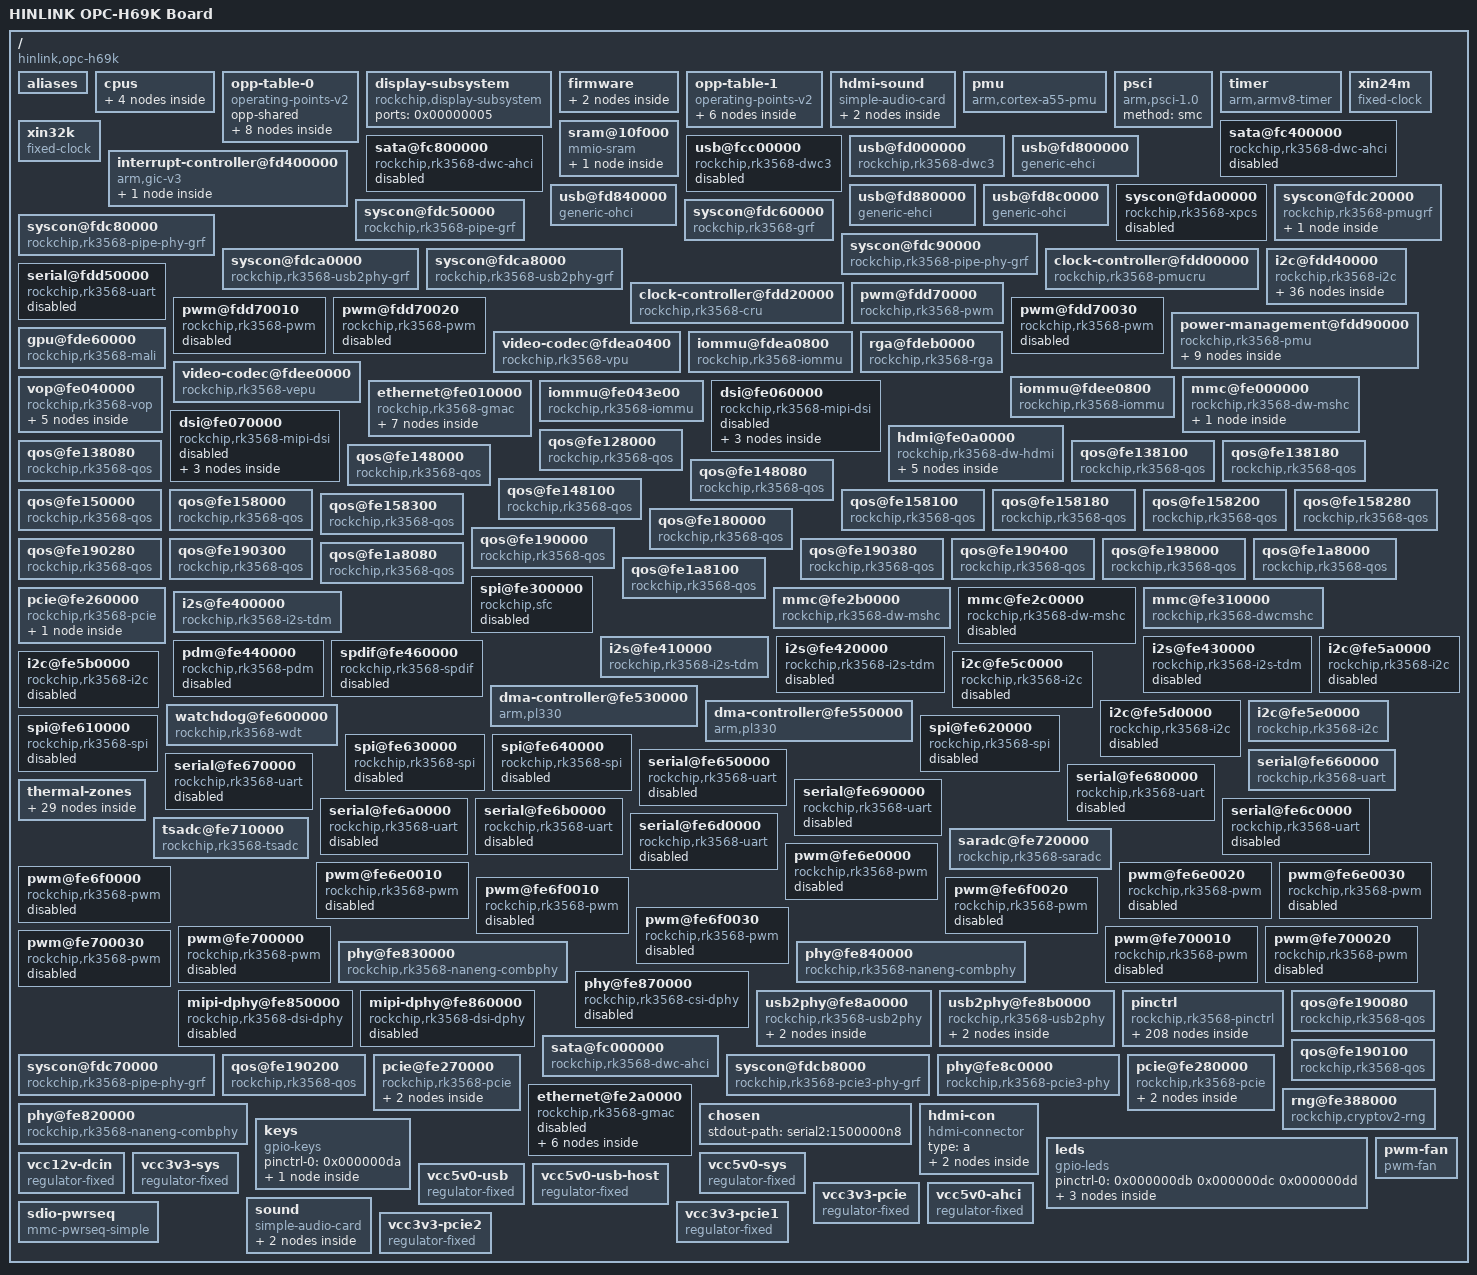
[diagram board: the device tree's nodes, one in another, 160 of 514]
/dts-v1/;
// version:		17
// last_comp_version:	16
// boot_cpuid_phys:	0x0

/ {
    interrupt-parent = <0x00000001>;
    #address-cells = <0x00000002>;
    #size-cells = <0x00000002>;
    compatible = "hinlink,opc-h69k", "rockchip,rk3568";
    model = "HINLINK OPC-H69K Board";
    aliases {
        gpio0 = "/pinctrl/gpio@fdd60000";
        gpio1 = "/pinctrl/gpio@fe740000";
        gpio2 = "/pinctrl/gpio@fe750000";
        gpio3 = "/pinctrl/gpio@fe760000";
        gpio4 = "/pinctrl/gpio@fe770000";
        i2c0 = "/i2c@fdd40000";
        i2c1 = "/i2c@fe5a0000";
        i2c2 = "/i2c@fe5b0000";
        i2c3 = "/i2c@fe5c0000";
        i2c4 = "/i2c@fe5d0000";
        i2c5 = "/i2c@fe5e0000";
        serial0 = "/serial@fdd50000";
        serial1 = "/serial@fe650000";
        serial2 = "/serial@fe660000";
        serial3 = "/serial@fe670000";
        serial4 = "/serial@fe680000";
        serial5 = "/serial@fe690000";
        serial6 = "/serial@fe6a0000";
        serial7 = "/serial@fe6b0000";
        serial8 = "/serial@fe6c0000";
        serial9 = "/serial@fe6d0000";
        spi0 = "/spi@fe610000";
        spi1 = "/spi@fe620000";
        spi2 = "/spi@fe630000";
        spi3 = "/spi@fe640000";
        mmc0 = "/mmc@fe310000";
        mmc1 = "/mmc@fe2b0000";
        led-boot = "/leds/work";
        led-failsafe = "/leds/work";
        led-running = "/leds/work";
        led-upgrade = "/leds/work";
        ethernet0 = "/ethernet@fe010000";
    };
    cpus {
        #address-cells = <0x00000002>;
        #size-cells = <0x00000000>;
        cpu@0 {
            device_type = "cpu";
            compatible = "arm,cortex-a55";
            reg = <0x00000000 0x00000000>;
            clocks = <0x00000002 0x00000000>;
            #cooling-cells = <0x00000002>;
            enable-method = "psci";
            operating-points-v2 = <0x00000003>;
            cpu-supply = <0x00000004>;
            phandle = <0x00000009>;
        };
        cpu@100 {
            device_type = "cpu";
            compatible = "arm,cortex-a55";
            reg = <0x00000000 0x00000100>;
            #cooling-cells = <0x00000002>;
            enable-method = "psci";
            operating-points-v2 = <0x00000003>;
            cpu-supply = <0x00000004>;
            phandle = <0x0000000a>;
        };
        cpu@200 {
            device_type = "cpu";
            compatible = "arm,cortex-a55";
            reg = <0x00000000 0x00000200>;
            #cooling-cells = <0x00000002>;
            enable-method = "psci";
            operating-points-v2 = <0x00000003>;
            cpu-supply = <0x00000004>;
            phandle = <0x0000000b>;
        };
        cpu@300 {
            device_type = "cpu";
            compatible = "arm,cortex-a55";
            reg = <0x00000000 0x00000300>;
            #cooling-cells = <0x00000002>;
            enable-method = "psci";
            operating-points-v2 = <0x00000003>;
            cpu-supply = <0x00000004>;
            phandle = <0x0000000c>;
        };
    };
    opp-table-0 {
        compatible = "operating-points-v2";
        opp-shared;
        phandle = <0x00000003>;
        opp-408000000 {
            opp-hz = <0x00000000 0x18519600>;
            opp-microvolt = <0x000dbba0 0x000dbba0 0x00118c30>;
            clock-latency-ns = <0x00009c40>;
        };
        opp-600000000 {
            opp-hz = <0x00000000 0x23c34600>;
            opp-microvolt = <0x000dbba0 0x000dbba0 0x00118c30>;
        };
        opp-816000000 {
            opp-hz = <0x00000000 0x30a32c00>;
            opp-microvolt = <0x000dbba0 0x000dbba0 0x00118c30>;
            opp-suspend;
        };
        opp-1104000000 {
            opp-hz = <0x00000000 0x41cdb400>;
            opp-microvolt = <0x000dbba0 0x000dbba0 0x00118c30>;
        };
        opp-1416000000 {
            opp-hz = <0x00000000 0x54667200>;
            opp-microvolt = <0x000dbba0 0x000dbba0 0x00118c30>;
        };
        opp-1608000000 {
            opp-hz = <0x00000000 0x5fd82200>;
            opp-microvolt = <0x000ee098 0x000ee098 0x00118c30>;
        };
        opp-1800000000 {
            opp-hz = <0x00000000 0x6b49d200>;
            opp-microvolt = <0x00100590 0x00100590 0x00118c30>;
        };
        opp-1992000000 {
            opp-hz = <0x00000000 0x76bb8200>;
            opp-microvolt = <0x00118c30 0x00118c30 0x00118c30>;
        };
    };
    display-subsystem {
        compatible = "rockchip,display-subsystem";
        ports = <0x00000005>;
    };
    firmware {
        scmi {
            compatible = "arm,scmi-smc";
            arm,smc-id = <0x82000010>;
            shmem = <0x00000006>;
            #address-cells = <0x00000001>;
            #size-cells = <0x00000000>;
            protocol@14 {
                reg = <0x00000014>;
                #clock-cells = <0x00000001>;
                phandle = <0x00000002>;
            };
        };
    };
    opp-table-1 {
        compatible = "operating-points-v2";
        phandle = <0x00000045>;
        opp-200000000 {
            opp-hz = <0x00000000 0x0bebc200>;
            opp-microvolt = <0x000cf850 0x000cf850 0x000f4240>;
        };
        opp-300000000 {
            opp-hz = <0x00000000 0x11e1a300>;
            opp-microvolt = <0x000cf850 0x000cf850 0x000f4240>;
        };
        opp-400000000 {
            opp-hz = <0x00000000 0x17d78400>;
            opp-microvolt = <0x000cf850 0x000cf850 0x000f4240>;
        };
        opp-600000000 {
            opp-hz = <0x00000000 0x23c34600>;
            opp-microvolt = <0x000dbba0 0x000dbba0 0x000f4240>;
        };
        opp-700000000 {
            opp-hz = <0x00000000 0x29b92700>;
            opp-microvolt = <0x000e7ef0 0x000e7ef0 0x000f4240>;
        };
        opp-800000000 {
            opp-hz = <0x00000000 0x2faf0800>;
            opp-microvolt = <0x000f4240 0x000f4240 0x000f4240>;
        };
    };
    hdmi-sound {
        compatible = "simple-audio-card";
        simple-audio-card,name = "HDMI";
        simple-audio-card,format = "i2s";
        simple-audio-card,mclk-fs = <0x00000100>;
        status = "okay";
        simple-audio-card,codec {
            sound-dai = <0x00000007>;
        };
        simple-audio-card,cpu {
            sound-dai = <0x00000008>;
        };
    };
    pmu {
        compatible = "arm,cortex-a55-pmu";
        interrupts = <0x00000000 0x000000e4 0x00000004 0x00000000 0x000000e5 0x00000004 0x00000000 0x000000e6 0x00000004 0x00000000 0x000000e7 0x00000004>;
        interrupt-affinity = <0x00000009 0x0000000a 0x0000000b 0x0000000c>;
    };
    psci {
        compatible = "arm,psci-1.0";
        method = "smc";
    };
    timer {
        compatible = "arm,armv8-timer";
        interrupts = <0x00000001 0x0000000d 0x00000004 0x00000001 0x0000000e 0x00000004 0x00000001 0x0000000b 0x00000004 0x00000001 0x0000000a 0x00000004>;
        arm,no-tick-in-suspend;
    };
    xin24m {
        compatible = "fixed-clock";
        clock-frequency = <0x016e3600>;
        clock-output-names = "xin24m";
        #clock-cells = <0x00000000>;
        phandle = <0x0000001c>;
    };
    xin32k {
        compatible = "fixed-clock";
        clock-frequency = <0x00008000>;
        clock-output-names = "xin32k";
        pinctrl-0 = <0x0000000d>;
        pinctrl-names = "default";
        #clock-cells = <0x00000000>;
    };
    sram@10f000 {
        compatible = "mmio-sram";
        reg = <0x00000000 0x0010f000 0x00000000 0x00000100>;
        #address-cells = <0x00000001>;
        #size-cells = <0x00000001>;
        ranges = <0x00000000 0x00000000 0x0010f000 0x00000100>;
        sram@0 {
            compatible = "arm,scmi-shmem";
            reg = <0x00000000 0x00000100>;
            phandle = <0x00000006>;
        };
    };
    sata@fc400000 {
        compatible = "rockchip,rk3568-dwc-ahci", "snps,dwc-ahci";
        reg = <0x00000000 0xfc400000 0x00000000 0x00001000>;
        clocks = <0x0000000e 0x0000009b 0x0000000e 0x0000009c 0x0000000e 0x0000009d>;
        clock-names = "sata", "pmalive", "rxoob";
        interrupts = <0x00000000 0x0000005f 0x00000004>;
        phys = <0x0000000f 0x00000001>;
        phy-names = "sata-phy";
        ports-implemented = <0x00000001>;
        power-domains = <0x00000010 0x0000000f>;
        status = "disabled";
    };
    sata@fc800000 {
        compatible = "rockchip,rk3568-dwc-ahci", "snps,dwc-ahci";
        reg = <0x00000000 0xfc800000 0x00000000 0x00001000>;
        clocks = <0x0000000e 0x000000a0 0x0000000e 0x000000a1 0x0000000e 0x000000a2>;
        clock-names = "sata", "pmalive", "rxoob";
        interrupts = <0x00000000 0x00000060 0x00000004>;
        phys = <0x00000011 0x00000001>;
        phy-names = "sata-phy";
        ports-implemented = <0x00000001>;
        power-domains = <0x00000010 0x0000000f>;
        status = "disabled";
    };
    usb@fcc00000 {
        compatible = "rockchip,rk3568-dwc3", "snps,dwc3";
        reg = <0x00000000 0xfcc00000 0x00000000 0x00400000>;
        interrupts = <0x00000000 0x000000a9 0x00000004>;
        clocks = <0x0000000e 0x000000a6 0x0000000e 0x000000a7 0x0000000e 0x000000a5>;
        clock-names = "ref_clk", "suspend_clk", "bus_clk";
        dr_mode = "otg";
        phy_type = "utmi_wide";
        power-domains = <0x00000010 0x0000000f>;
        resets = <0x0000000e 0x00000094>;
        snps,dis_u2_susphy_quirk;
        status = "disabled";
        phys = <0x00000012 0x00000013 0x00000004>;
        phy-names = "usb2-phy", "usb3-phy";
    };
    usb@fd000000 {
        compatible = "rockchip,rk3568-dwc3", "snps,dwc3";
        reg = <0x00000000 0xfd000000 0x00000000 0x00400000>;
        interrupts = <0x00000000 0x000000aa 0x00000004>;
        clocks = <0x0000000e 0x000000a9 0x0000000e 0x000000aa 0x0000000e 0x000000a8>;
        clock-names = "ref_clk", "suspend_clk", "bus_clk";
        dr_mode = "host";
        phys = <0x00000014 0x0000000f 0x00000004>;
        phy-names = "usb2-phy", "usb3-phy";
        phy_type = "utmi_wide";
        power-domains = <0x00000010 0x0000000f>;
        resets = <0x0000000e 0x00000095>;
        snps,dis_u2_susphy_quirk;
        status = "okay";
    };
    interrupt-controller@fd400000 {
        compatible = "arm,gic-v3";
        #interrupt-cells = <0x00000003>;
        #address-cells = <0x00000002>;
        #size-cells = <0x00000002>;
        ranges;
        interrupt-controller;
        reg = <0x00000000 0xfd400000 0x00000000 0x00010000 0x00000000 0xfd460000 0x00000000 0x000c0000>;
        interrupts = <0x00000001 0x00000009 0x00000004>;
        phandle = <0x00000001>;
        interrupt-controller@fd440000 {
            compatible = "arm,gic-v3-its";
            msi-controller;
            #msi-cells = <0x00000001>;
            reg = <0x00000000 0xfd440000 0x00000000 0x00020000>;
            phandle = <0x00000065>;
        };
    };
    usb@fd800000 {
        compatible = "generic-ehci";
        reg = <0x00000000 0xfd800000 0x00000000 0x00040000>;
        interrupts = <0x00000000 0x00000082 0x00000004>;
        clocks = <0x0000000e 0x000000bd 0x0000000e 0x000000be 0x0000000e 0x000000bc>;
        phys = <0x00000015>;
        phy-names = "usb";
        status = "okay";
    };
    usb@fd840000 {
        compatible = "generic-ohci";
        reg = <0x00000000 0xfd840000 0x00000000 0x00040000>;
        interrupts = <0x00000000 0x00000083 0x00000004>;
        clocks = <0x0000000e 0x000000bd 0x0000000e 0x000000be 0x0000000e 0x000000bc>;
        phys = <0x00000015>;
        phy-names = "usb";
        status = "okay";
    };
    usb@fd880000 {
        compatible = "generic-ehci";
        reg = <0x00000000 0xfd880000 0x00000000 0x00040000>;
        interrupts = <0x00000000 0x00000085 0x00000004>;
        clocks = <0x0000000e 0x000000bf 0x0000000e 0x000000c0 0x0000000e 0x000000bc>;
        phys = <0x00000016>;
        phy-names = "usb";
        status = "okay";
    };
    usb@fd8c0000 {
        compatible = "generic-ohci";
        reg = <0x00000000 0xfd8c0000 0x00000000 0x00040000>;
        interrupts = <0x00000000 0x00000086 0x00000004>;
        clocks = <0x0000000e 0x000000bf 0x0000000e 0x000000c0 0x0000000e 0x000000bc>;
        phys = <0x00000016>;
        phy-names = "usb";
        status = "okay";
    };
    syscon@fda00000 {
        compatible = "rockchip,rk3568-xpcs", "syscon";
        reg = <0x00000000 0xfda00000 0x00000000 0x00200000>;
        status = "disabled";
    };
    syscon@fdc20000 {
        compatible = "rockchip,rk3568-pmugrf", "syscon", "simple-mfd";
        reg = <0x00000000 0xfdc20000 0x00000000 0x00010000>;
        phandle = <0x000000c3>;
        io-domains {
            compatible = "rockchip,rk3568-pmu-io-voltage-domain";
            status = "okay";
            pmuio1-supply = <0x00000017>;
            pmuio2-supply = <0x00000017>;
            vccio1-supply = <0x00000018>;
            vccio2-supply = <0x00000019>;
            vccio3-supply = <0x0000001a>;
            vccio4-supply = <0x00000019>;
            vccio5-supply = <0x0000001b>;
            vccio6-supply = <0x00000019>;
            vccio7-supply = <0x0000001b>;
        };
    };
    syscon@fdc50000 {
        reg = <0x00000000 0xfdc50000 0x00000000 0x00001000>;
        compatible = "rockchip,rk3568-pipe-grf", "syscon";
        phandle = <0x000000bd>;
    };
    syscon@fdc60000 {
        compatible = "rockchip,rk3568-grf", "syscon", "simple-mfd";
        reg = <0x00000000 0xfdc60000 0x00000000 0x00010000>;
        phandle = <0x0000001e>;
    };
    syscon@fdc80000 {
        compatible = "rockchip,rk3568-pipe-phy-grf", "syscon";
        reg = <0x00000000 0xfdc80000 0x00000000 0x00001000>;
        phandle = <0x000000be>;
    };
    syscon@fdc90000 {
        compatible = "rockchip,rk3568-pipe-phy-grf", "syscon";
        reg = <0x00000000 0xfdc90000 0x00000000 0x00001000>;
        phandle = <0x000000bf>;
    };
    syscon@fdca0000 {
        compatible = "rockchip,rk3568-usb2phy-grf", "syscon";
        reg = <0x00000000 0xfdca0000 0x00000000 0x00008000>;
        phandle = <0x000000c0>;
    };
    syscon@fdca8000 {
        compatible = "rockchip,rk3568-usb2phy-grf", "syscon";
        reg = <0x00000000 0xfdca8000 0x00000000 0x00008000>;
        phandle = <0x000000c2>;
    };
    clock-controller@fdd00000 {
        compatible = "rockchip,rk3568-pmucru";
        reg = <0x00000000 0xfdd00000 0x00000000 0x00001000>;
        #clock-cells = <0x00000001>;
        #reset-cells = <0x00000001>;
        phandle = <0x0000001d>;
    };
    clock-controller@fdd20000 {
        compatible = "rockchip,rk3568-cru";
        reg = <0x00000000 0xfdd20000 0x00000000 0x00001000>;
        clocks = <0x0000001c>;
        clock-names = "xin24m";
        #clock-cells = <0x00000001>;
        #reset-cells = <0x00000001>;
        assigned-clocks = <0x0000001d 0x00000005 0x0000000e 0x00000004 0x0000001d 0x00000001>;
        assigned-clock-rates = <0x00008000 0x47868c00 0x0bebc200>;
        assigned-clock-parents = <0x0000001d 0x00000008>;
        rockchip,grf = <0x0000001e>;
        phandle = <0x0000000e>;
    };
    i2c@fdd40000 {
        compatible = "rockchip,rk3568-i2c", "rockchip,rk3399-i2c";
        reg = <0x00000000 0xfdd40000 0x00000000 0x00001000>;
        interrupts = <0x00000000 0x0000002e 0x00000004>;
        clocks = <0x0000001d 0x00000007 0x0000001d 0x0000002d>;
        clock-names = "i2c", "pclk";
        pinctrl-0 = <0x0000001f>;
        pinctrl-names = "default";
        #address-cells = <0x00000001>;
        #size-cells = <0x00000000>;
        status = "okay";
        regulator@1c {
            compatible = "tcs,tcs4525";
            reg = <0x0000001c>;
            fcs,suspend-voltage-selector = <0x00000001>;
            regulator-name = "vdd_cpu";
            regulator-always-on;
            regulator-boot-on;
            regulator-min-microvolt = <0x000adf34>;
            regulator-max-microvolt = <0x001535b0>;
            regulator-ramp-delay = <0x000008fc>;
            vin-supply = <0x00000020>;
            phandle = <0x00000004>;
            regulator-state-mem {
                regulator-off-in-suspend;
            };
        };
        pmic@20 {
            compatible = "rockchip,rk809";
            reg = <0x00000020>;
            interrupt-parent = <0x00000021>;
            interrupts = <0x00000003 0x00000008>;
            assigned-clocks = <0x0000000e 0x00000048>;
            assigned-clock-parents = <0x0000000e 0x00000196>;
            #clock-cells = <0x00000001>;
            clock-names = "mclk";
            clocks = <0x0000000e 0x00000048>;
            pinctrl-names = "default";
            pinctrl-0 = <0x00000022 0x00000023>;
            rockchip,system-power-controller;
            #sound-dai-cells = <0x00000000>;
            wakeup-source;
            vcc1-supply = <0x00000024>;
            vcc2-supply = <0x00000024>;
            vcc3-supply = <0x00000024>;
            vcc4-supply = <0x00000024>;
            vcc5-supply = <0x00000024>;
            vcc6-supply = <0x00000024>;
            vcc7-supply = <0x00000024>;
            vcc8-supply = <0x00000024>;
            vcc9-supply = <0x00000024>;
            phandle = <0x000000e2>;
            regulators {
                DCDC_REG1 {
                    regulator-always-on;
                    regulator-boot-on;
                    regulator-initial-mode = <0x00000002>;
                    regulator-min-microvolt = <0x0007a120>;
                    regulator-max-microvolt = <0x00149970>;
                    regulator-name = "vdd_logic";
                    regulator-ramp-delay = <0x00001771>;
                    regulator-state-mem {
                        regulator-off-in-suspend;
                    };
                };
                DCDC_REG2 {
                    regulator-always-on;
                    regulator-initial-mode = <0x00000002>;
                    regulator-min-microvolt = <0x0007a120>;
                    regulator-max-microvolt = <0x00149970>;
                    regulator-name = "vdd_gpu";
                    regulator-ramp-delay = <0x00001771>;
                    phandle = <0x00000046>;
                    regulator-state-mem {
                        regulator-off-in-suspend;
                    };
                };
                DCDC_REG3 {
                    regulator-always-on;
                    regulator-boot-on;
                    regulator-initial-mode = <0x00000002>;
                    regulator-name = "vcc_ddr";
                    regulator-state-mem {
                        regulator-on-in-suspend;
                    };
                };
                DCDC_REG4 {
                    regulator-initial-mode = <0x00000002>;
                    regulator-min-microvolt = <0x0007a120>;
                    regulator-max-microvolt = <0x00149970>;
                    regulator-name = "vdd_npu";
                    regulator-ramp-delay = <0x00001771>;
                    regulator-state-mem {
                        regulator-off-in-suspend;
                    };
                };
                DCDC_REG5 {
                    regulator-always-on;
                    regulator-boot-on;
                    regulator-min-microvolt = <0x001b7740>;
                    regulator-max-microvolt = <0x001b7740>;
                    regulator-name = "vcc_1v8";
                    phandle = <0x00000019>;
                    regulator-state-mem {
                        regulator-off-in-suspend;
                    };
                };
                LDO_REG1 {
                    regulator-name = "vdda0v9_image";
                    regulator-min-microvolt = <0x000dbba0>;
                    regulator-max-microvolt = <0x000dbba0>;
                    phandle = <0x00000060>;
                    regulator-state-mem {
                        regulator-off-in-suspend;
                    };
                };
                LDO_REG2 {
                    regulator-always-on;
                    regulator-boot-on;
                    regulator-min-microvolt = <0x000dbba0>;
                    regulator-max-microvolt = <0x000dbba0>;
                    regulator-name = "vdda_0v9";
                    regulator-state-mem {
                        regulator-off-in-suspend;
                    };
                };
                LDO_REG3 {
                    regulator-always-on;
                    regulator-boot-on;
                    regulator-min-microvolt = <0x000dbba0>;
                    regulator-max-microvolt = <0x000dbba0>;
                    regulator-name = "vdda0v9_pmu";
                    regulator-state-mem {
                        regulator-on-in-suspend;
                        regulator-suspend-microvolt = <0x000dbba0>;
                    };
                };
                LDO_REG4 {
                    regulator-always-on;
                    regulator-min-microvolt = <0x00325aa0>;
                    regulator-max-microvolt = <0x00325aa0>;
                    regulator-name = "vccio_acodec";
                    phandle = <0x00000018>;
                    regulator-state-mem {
                        regulator-off-in-suspend;
                    };
                };
                LDO_REG5 {
                    regulator-min-microvolt = <0x001b7740>;
                    regulator-max-microvolt = <0x00325aa0>;
                    regulator-name = "vccio_sd";
                    phandle = <0x0000001a>;
                    regulator-state-mem {
                        regulator-off-in-suspend;
                    };
                };
                LDO_REG6 {
                    regulator-always-on;
                    regulator-boot-on;
                    regulator-min-microvolt = <0x00325aa0>;
                    regulator-max-microvolt = <0x00325aa0>;
                    regulator-name = "vcc3v3_pmu";
                    phandle = <0x00000017>;
                    regulator-state-mem {
                        regulator-on-in-suspend;
                        regulator-suspend-microvolt = <0x00325aa0>;
                    };
                };
                LDO_REG7 {
                    regulator-always-on;
                    regulator-boot-on;
                    regulator-min-microvolt = <0x001b7740>;
                    regulator-max-microvolt = <0x001b7740>;
                    regulator-name = "vcca_1v8";
                    phandle = <0x000000b0>;
                    regulator-state-mem {
                        regulator-off-in-suspend;
                    };
                };
                LDO_REG8 {
                    regulator-always-on;
                    regulator-boot-on;
                    regulator-min-microvolt = <0x001b7740>;
                    regulator-max-microvolt = <0x001b7740>;
                    regulator-name = "vcca1v8_pmu";
                    regulator-state-mem {
                        regulator-on-in-suspend;
                        regulator-suspend-microvolt = <0x001b7740>;
                    };
                };
                LDO_REG9 {
                    regulator-min-microvolt = <0x001b7740>;
                    regulator-max-microvolt = <0x001b7740>;
                    regulator-name = "vcca1v8_image";
                    phandle = <0x00000061>;
                    regulator-state-mem {
                        regulator-off-in-suspend;
                    };
                };
                SWITCH_REG1 {
                    regulator-name = "vcc_3v3";
                    regulator-always-on;
                    regulator-boot-on;
                    phandle = <0x0000001b>;
                    regulator-state-mem {
                        regulator-off-in-suspend;
                    };
                };
                SWITCH_REG2 {
                    regulator-name = "vcc3v3_sd";
                    phandle = <0x0000006c>;
                    regulator-state-mem {
                        regulator-off-in-suspend;
                    };
                };
            };
        };
    };
    serial@fdd50000 {
        compatible = "rockchip,rk3568-uart", "snps,dw-apb-uart";
        reg = <0x00000000 0xfdd50000 0x00000000 0x00000100>;
        interrupts = <0x00000000 0x00000074 0x00000004>;
        clocks = <0x0000001d 0x0000000b 0x0000001d 0x0000002c>;
        clock-names = "baudclk", "apb_pclk";
        dmas = <0x00000025 0x00000000 0x00000025 0x00000001>;
        pinctrl-0 = <0x00000026>;
        pinctrl-names = "default";
        reg-io-width = <0x00000004>;
        reg-shift = <0x00000002>;
        status = "disabled";
    };
    pwm@fdd70000 {
        compatible = "rockchip,rk3568-pwm", "rockchip,rk3328-pwm";
        reg = <0x00000000 0xfdd70000 0x00000000 0x00000010>;
        clocks = <0x0000001d 0x0000000d 0x0000001d 0x00000030>;
        clock-names = "pwm", "pclk";
        pinctrl-0 = <0x00000027>;
        pinctrl-names = "default";
        #pwm-cells = <0x00000003>;
        status = "okay";
        phandle = <0x000000e3>;
    };
    pwm@fdd70010 {
        compatible = "rockchip,rk3568-pwm", "rockchip,rk3328-pwm";
        reg = <0x00000000 0xfdd70010 0x00000000 0x00000010>;
        clocks = <0x0000001d 0x0000000d 0x0000001d 0x00000030>;
        clock-names = "pwm", "pclk";
        pinctrl-0 = <0x00000028>;
        pinctrl-names = "default";
        #pwm-cells = <0x00000003>;
        status = "disabled";
    };
    pwm@fdd70020 {
        compatible = "rockchip,rk3568-pwm", "rockchip,rk3328-pwm";
        reg = <0x00000000 0xfdd70020 0x00000000 0x00000010>;
        clocks = <0x0000001d 0x0000000d 0x0000001d 0x00000030>;
        clock-names = "pwm", "pclk";
        pinctrl-0 = <0x00000029>;
        pinctrl-names = "default";
        #pwm-cells = <0x00000003>;
        status = "disabled";
    };
    pwm@fdd70030 {
        compatible = "rockchip,rk3568-pwm", "rockchip,rk3328-pwm";
        reg = <0x00000000 0xfdd70030 0x00000000 0x00000010>;
        clocks = <0x0000001d 0x0000000d 0x0000001d 0x00000030>;
        clock-names = "pwm", "pclk";
        pinctrl-0 = <0x0000002a>;
        pinctrl-names = "default";
        #pwm-cells = <0x00000003>;
        status = "disabled";
    };
    power-management@fdd90000 {
        compatible = "rockchip,rk3568-pmu", "syscon", "simple-mfd";
        reg = <0x00000000 0xfdd90000 0x00000000 0x00001000>;
        power-controller {
            compatible = "rockchip,rk3568-power-controller";
            #power-domain-cells = <0x00000001>;
            #address-cells = <0x00000001>;
            #size-cells = <0x00000000>;
            phandle = <0x00000010>;
            power-domain@7 {
                reg = <0x00000007>;
                clocks = <0x0000000e 0x00000019 0x0000000e 0x0000001a>;
                pm_qos = <0x0000002b>;
                #power-domain-cells = <0x00000000>;
            };
            power-domain@8 {
                reg = <0x00000008>;
                clocks = <0x0000000e 0x000000cc 0x0000000e 0x000000cd>;
                pm_qos = <0x0000002c 0x0000002d 0x0000002e>;
                #power-domain-cells = <0x00000000>;
            };
            power-domain@9 {
                reg = <0x00000009>;
                clocks = <0x0000000e 0x000000da 0x0000000e 0x000000db 0x0000000e 0x000000dc>;
                pm_qos = <0x0000002f 0x00000030 0x00000031>;
                #power-domain-cells = <0x00000000>;
            };
            power-domain@10 {
                reg = <0x0000000a>;
                clocks = <0x0000000e 0x000000f1 0x0000000e 0x000000f2>;
                pm_qos = <0x00000032 0x00000033 0x00000034 0x00000035 0x00000036 0x00000037>;
                #power-domain-cells = <0x00000000>;
            };
            power-domain@11 {
                reg = <0x0000000b>;
                clocks = <0x0000000e 0x000000ed>;
                pm_qos = <0x00000038>;
                #power-domain-cells = <0x00000000>;
            };
            power-domain@13 {
                clocks = <0x0000000e 0x00000107>;
                reg = <0x0000000d>;
                pm_qos = <0x00000039>;
                #power-domain-cells = <0x00000000>;
            };
            power-domain@14 {
                reg = <0x0000000e>;
                clocks = <0x0000000e 0x00000102>;
                pm_qos = <0x0000003a 0x0000003b 0x0000003c>;
                #power-domain-cells = <0x00000000>;
            };
            power-domain@15 {
                reg = <0x0000000f>;
                clocks = <0x0000000e 0x0000007f>;
                pm_qos = <0x0000003d 0x0000003e 0x0000003f 0x00000040 0x00000041 0x00000042 0x00000043 0x00000044>;
                #power-domain-cells = <0x00000000>;
            };
        };
    };
    gpu@fde60000 {
        compatible = "rockchip,rk3568-mali", "arm,mali-bifrost";
        reg = <0x00000000 0xfde60000 0x00000000 0x00004000>;
        interrupts = <0x00000000 0x00000028 0x00000004 0x00000000 0x00000029 0x00000004 0x00000000 0x00000027 0x00000004>;
        interrupt-names = "job", "mmu", "gpu";
        clocks = <0x00000002 0x00000001 0x0000000e 0x0000001b>;
        clock-names = "gpu", "bus";
        #cooling-cells = <0x00000002>;
        operating-points-v2 = <0x00000045>;
        power-domains = <0x00000010 0x00000007>;
        status = "okay";
        mali-supply = <0x00000046>;
        phandle = <0x000000ad>;
    };
    video-codec@fdea0400 {
        compatible = "rockchip,rk3568-vpu";
        reg = <0x00000000 0xfdea0000 0x00000000 0x00000800>;
        interrupts = <0x00000000 0x0000008b 0x00000004>;
        interrupt-names = "vdpu";
        clocks = <0x0000000e 0x000000ee 0x0000000e 0x000000ef>;
        clock-names = "aclk", "hclk";
        iommus = <0x00000047>;
        power-domains = <0x00000010 0x0000000b>;
    };
    iommu@fdea0800 {
        compatible = "rockchip,rk3568-iommu";
        reg = <0x00000000 0xfdea0800 0x00000000 0x00000040>;
        interrupts = <0x00000000 0x0000008a 0x00000004>;
        clock-names = "aclk", "iface";
        clocks = <0x0000000e 0x000000ee 0x0000000e 0x000000ef>;
        power-domains = <0x00000010 0x0000000b>;
        #iommu-cells = <0x00000000>;
        phandle = <0x00000047>;
    };
    rga@fdeb0000 {
        compatible = "rockchip,rk3568-rga", "rockchip,rk3288-rga";
        reg = <0x00000000 0xfdeb0000 0x00000000 0x00000180>;
        interrupts = <0x00000000 0x0000005a 0x00000004>;
        clocks = <0x0000000e 0x000000f3 0x0000000e 0x000000f4 0x0000000e 0x000000f5>;
        clock-names = "aclk", "hclk", "sclk";
        resets = <0x0000000e 0x00000126 0x0000000e 0x00000124 0x0000000e 0x00000125>;
        reset-names = "core", "axi", "ahb";
        power-domains = <0x00000010 0x0000000a>;
    };
    video-codec@fdee0000 {
        compatible = "rockchip,rk3568-vepu";
        reg = <0x00000000 0xfdee0000 0x00000000 0x00000800>;
        interrupts = <0x00000000 0x00000040 0x00000004>;
        clocks = <0x0000000e 0x000000fd 0x0000000e 0x000000fe>;
        clock-names = "aclk", "hclk";
        iommus = <0x00000048>;
        power-domains = <0x00000010 0x0000000a>;
    };
    iommu@fdee0800 {
        compatible = "rockchip,rk3568-iommu";
        reg = <0x00000000 0xfdee0800 0x00000000 0x00000040>;
        interrupts = <0x00000000 0x0000003f 0x00000004>;
        clocks = <0x0000000e 0x000000fd 0x0000000e 0x000000fe>;
        clock-names = "aclk", "iface";
        power-domains = <0x00000010 0x0000000a>;
        #iommu-cells = <0x00000000>;
        phandle = <0x00000048>;
    };
    mmc@fe000000 {
        compatible = "rockchip,rk3568-dw-mshc", "rockchip,rk3288-dw-mshc";
        reg = <0x00000000 0xfe000000 0x00000000 0x00004000>;
        interrupts = <0x00000000 0x00000064 0x00000004>;
        clocks = <0x0000000e 0x000000c1 0x0000000e 0x000000c2 0x0000000e 0x0000018e 0x0000000e 0x0000018f>;
        clock-names = "biu", "ciu", "ciu-drive", "ciu-sample";
        fifo-depth = <0x00000100>;
        max-frequency = <0x08f0d180>;
        resets = <0x0000000e 0x000000eb>;
        reset-names = "reset";
        status = "okay";
        bus-width = <0x00000004>;
        disable-wp;
        cap-sd-highspeed;
        cap-sdio-irq;
        keep-power-in-suspend;
        mmc-pwrseq = <0x00000049>;
        non-removable;
        pinctrl-names = "default";
        pinctrl-0 = <0x0000004a 0x0000004b 0x0000004c>;
        sd-uhs-sdr12;
        sd-uhs-sdr25;
        sd-uhs-sdr50;
        sd-uhs-sdr104;
        vmmc-supply = <0x00000024>;
        vqmmc-supply = <0x00000019>;
        sdio_wifi@0 {
            reg = <0x00000000>;
            interrupt-parent = <0x0000004d>;
            interrupts = <0x0000001d 0x00000004>;
            interrupt-names = "host-wake";
            pinctrl-names = "default";
            pinctrl-0 = <0x0000004e>;
        };
    };
    ethernet@fe010000 {
        compatible = "rockchip,rk3568-gmac", "snps,dwmac-4.20a";
        reg = <0x00000000 0xfe010000 0x00000000 0x00010000>;
        interrupts = <0x00000000 0x00000020 0x00000004 0x00000000 0x0000001d 0x00000004>;
        interrupt-names = "macirq", "eth_wake_irq";
        clocks = <0x0000000e 0x00000186 0x0000000e 0x00000189 0x0000000e 0x00000189 0x0000000e 0x000000c7 0x0000000e 0x000000c3 0x0000000e 0x000000c4 0x0000000e 0x00000189 0x0000000e 0x000000c8>;
        clock-names = "stmmaceth", "mac_clk_rx", "mac_clk_tx", "clk_mac_refout", "aclk_mac", "pclk_mac", "clk_mac_speed", "ptp_ref";
        resets = <0x0000000e 0x000000ec>;
        reset-names = "stmmaceth";
        rockchip,grf = <0x0000001e>;
        snps,axi-config = <0x0000004f>;
        snps,mixed-burst;
        snps,mtl-rx-config = <0x00000050>;
        snps,mtl-tx-config = <0x00000051>;
        snps,tso;
        status = "okay";
        assigned-clocks = <0x0000000e 0x00000189 0x0000000e 0x00000186>;
        assigned-clock-parents = <0x0000000e 0x00000187>;
        assigned-clock-rates = <0x00000000 0x07735940>;
        clock_in_out = "output";
        phy-mode = "rgmii-id";
        pinctrl-names = "default";
        pinctrl-0 = <0x00000052 0x00000053 0x00000054 0x00000055 0x00000056>;
        snps,reset-gpio = <0x00000057 0x00000008 0x00000001>;
        snps,reset-active-low;
        snps,reset-delays-us = <0x00000000 0x00004e20 0x000186a0>;
        tx_delay = <0x0000004f>;
        rx_delay = <0x00000026>;
        phy-handle = <0x00000058>;
        mdio {
            compatible = "snps,dwmac-mdio";
            #address-cells = <0x00000001>;
            #size-cells = <0x00000000>;
            ethernet-phy@0 {
                compatible = "ethernet-phy-ieee802.3-c22";
                reg = <0x00000000>;
                phandle = <0x00000058>;
            };
        };
        stmmac-axi-config {
            snps,blen = <0x00000000 0x00000000 0x00000000 0x00000000 0x00000010 0x00000008 0x00000004>;
            snps,rd_osr_lmt = <0x00000008>;
            snps,wr_osr_lmt = <0x00000004>;
            phandle = <0x0000004f>;
        };
        rx-queues-config {
            snps,rx-queues-to-use = <0x00000001>;
            phandle = <0x00000050>;
            queue0 {
            };
        };
        tx-queues-config {
            snps,tx-queues-to-use = <0x00000001>;
            phandle = <0x00000051>;
            queue0 {
            };
        };
    };
    vop@fe040000 {
        reg = <0x00000000 0xfe040000 0x00000000 0x00003000 0x00000000 0xfe044000 0x00000000 0x00001000>;
        reg-names = "vop", "gamma-lut";
        interrupts = <0x00000000 0x00000094 0x00000004>;
        clocks = <0x0000000e 0x000000dd 0x0000000e 0x000000de 0x0000000e 0x000000df 0x0000000e 0x000000e0 0x0000000e 0x000000e1>;
        clock-names = "aclk", "hclk", "dclk_vp0", "dclk_vp1", "dclk_vp2";
        iommus = <0x00000059>;
        power-domains = <0x00000010 0x00000009>;
        rockchip,grf = <0x0000001e>;
        status = "okay";
        compatible = "rockchip,rk3568-vop";
        assigned-clocks = <0x0000000e 0x000000df 0x0000000e 0x000000e0>;
        assigned-clock-parents = <0x0000001d 0x00000002 0x0000000e 0x00000005>;
        ports {
            #address-cells = <0x00000001>;
            #size-cells = <0x00000000>;
            phandle = <0x00000005>;
            port@0 {
                reg = <0x00000000>;
                #address-cells = <0x00000001>;
                #size-cells = <0x00000000>;
                endpoint@2 {
                    reg = <0x00000002>;
                    remote-endpoint = <0x0000005a>;
                    phandle = <0x00000062>;
                };
            };
            port@1 {
                reg = <0x00000001>;
                #address-cells = <0x00000001>;
                #size-cells = <0x00000000>;
            };
            port@2 {
                reg = <0x00000002>;
                #address-cells = <0x00000001>;
                #size-cells = <0x00000000>;
            };
        };
    };
    iommu@fe043e00 {
        compatible = "rockchip,rk3568-iommu";
        reg = <0x00000000 0xfe043e00 0x00000000 0x00000100 0x00000000 0xfe043f00 0x00000000 0x00000100>;
        interrupts = <0x00000000 0x00000094 0x00000004>;
        clocks = <0x0000000e 0x000000dd 0x0000000e 0x000000de>;
        clock-names = "aclk", "iface";
        #iommu-cells = <0x00000000>;
        power-domains = <0x00000010 0x00000009>;
        status = "okay";
        phandle = <0x00000059>;
    };
    dsi@fe060000 {
        compatible = "rockchip,rk3568-mipi-dsi", "snps,dw-mipi-dsi";
        reg = <0x00000000 0xfe060000 0x00000000 0x00010000>;
        interrupts = <0x00000000 0x00000044 0x00000004>;
        clock-names = "pclk";
        clocks = <0x0000000e 0x000000e8>;
        phy-names = "dphy";
        phys = <0x0000005b>;
        power-domains = <0x00000010 0x00000009>;
        reset-names = "apb";
        resets = <0x0000000e 0x00000110>;
        rockchip,grf = <0x0000001e>;
        status = "disabled";
        ports {
            #address-cells = <0x00000001>;
            #size-cells = <0x00000000>;
            port@0 {
                reg = <0x00000000>;
            };
            port@1 {
                reg = <0x00000001>;
            };
        };
    };
    dsi@fe070000 {
        compatible = "rockchip,rk3568-mipi-dsi", "snps,dw-mipi-dsi";
        reg = <0x00000000 0xfe070000 0x00000000 0x00010000>;
        interrupts = <0x00000000 0x00000045 0x00000004>;
        clock-names = "pclk";
        clocks = <0x0000000e 0x000000e9>;
        phy-names = "dphy";
        phys = <0x0000005c>;
        power-domains = <0x00000010 0x00000009>;
        reset-names = "apb";
        resets = <0x0000000e 0x00000111>;
        rockchip,grf = <0x0000001e>;
        status = "disabled";
        ports {
            #address-cells = <0x00000001>;
            #size-cells = <0x00000000>;
            port@0 {
                reg = <0x00000000>;
            };
            port@1 {
                reg = <0x00000001>;
            };
        };
    };
    hdmi@fe0a0000 {
        compatible = "rockchip,rk3568-dw-hdmi";
        reg = <0x00000000 0xfe0a0000 0x00000000 0x00020000>;
        interrupts = <0x00000000 0x0000002d 0x00000004>;
        clocks = <0x0000000e 0x000000e6 0x0000000e 0x000000e7 0x0000000e 0x00000193 0x0000001d 0x00000028 0x0000000e 0x000000da>;
        clock-names = "iahb", "isfr", "cec", "ref";
        pinctrl-names = "default";
        pinctrl-0 = <0x0000005d 0x0000005e 0x0000005f>;
        power-domains = <0x00000010 0x00000009>;
        reg-io-width = <0x00000004>;
        rockchip,grf = <0x0000001e>;
        #sound-dai-cells = <0x00000000>;
        status = "okay";
        avdd-0v9-supply = <0x00000060>;
        avdd-1v8-supply = <0x00000061>;
        phandle = <0x00000007>;
        ports {
            #address-cells = <0x00000001>;
            #size-cells = <0x00000000>;
            port@0 {
                reg = <0x00000000>;
                endpoint {
                    remote-endpoint = <0x00000062>;
                    phandle = <0x0000005a>;
                };
            };
            port@1 {
                reg = <0x00000001>;
                endpoint {
                    remote-endpoint = <0x00000063>;
                    phandle = <0x000000d9>;
                };
            };
        };
    };
    qos@fe128000 {
        compatible = "rockchip,rk3568-qos", "syscon";
        reg = <0x00000000 0xfe128000 0x00000000 0x00000020>;
        phandle = <0x0000002b>;
    };
    qos@fe138080 {
        compatible = "rockchip,rk3568-qos", "syscon";
        reg = <0x00000000 0xfe138080 0x00000000 0x00000020>;
        phandle = <0x0000003a>;
    };
    qos@fe138100 {
        compatible = "rockchip,rk3568-qos", "syscon";
        reg = <0x00000000 0xfe138100 0x00000000 0x00000020>;
        phandle = <0x0000003b>;
    };
    qos@fe138180 {
        compatible = "rockchip,rk3568-qos", "syscon";
        reg = <0x00000000 0xfe138180 0x00000000 0x00000020>;
        phandle = <0x0000003c>;
    };
    qos@fe148000 {
        compatible = "rockchip,rk3568-qos", "syscon";
        reg = <0x00000000 0xfe148000 0x00000000 0x00000020>;
        phandle = <0x0000002c>;
    };
    qos@fe148080 {
        compatible = "rockchip,rk3568-qos", "syscon";
        reg = <0x00000000 0xfe148080 0x00000000 0x00000020>;
        phandle = <0x0000002d>;
    };
    qos@fe148100 {
        compatible = "rockchip,rk3568-qos", "syscon";
        reg = <0x00000000 0xfe148100 0x00000000 0x00000020>;
        phandle = <0x0000002e>;
    };
    qos@fe150000 {
        compatible = "rockchip,rk3568-qos", "syscon";
        reg = <0x00000000 0xfe150000 0x00000000 0x00000020>;
        phandle = <0x00000038>;
    };
    qos@fe158000 {
        compatible = "rockchip,rk3568-qos", "syscon";
        reg = <0x00000000 0xfe158000 0x00000000 0x00000020>;
        phandle = <0x00000032>;
    };
    qos@fe158100 {
        compatible = "rockchip,rk3568-qos", "syscon";
        reg = <0x00000000 0xfe158100 0x00000000 0x00000020>;
        phandle = <0x00000033>;
    };
    qos@fe158180 {
        compatible = "rockchip,rk3568-qos", "syscon";
        reg = <0x00000000 0xfe158180 0x00000000 0x00000020>;
        phandle = <0x00000034>;
    };
    qos@fe158200 {
        compatible = "rockchip,rk3568-qos", "syscon";
        reg = <0x00000000 0xfe158200 0x00000000 0x00000020>;
        phandle = <0x00000035>;
    };
    qos@fe158280 {
        compatible = "rockchip,rk3568-qos", "syscon";
        reg = <0x00000000 0xfe158280 0x00000000 0x00000020>;
        phandle = <0x00000036>;
    };
    qos@fe158300 {
        compatible = "rockchip,rk3568-qos", "syscon";
        reg = <0x00000000 0xfe158300 0x00000000 0x00000020>;
        phandle = <0x00000037>;
    };
    qos@fe180000 {
        compatible = "rockchip,rk3568-qos", "syscon";
        reg = <0x00000000 0xfe180000 0x00000000 0x00000020>;
    };
    qos@fe190000 {
        compatible = "rockchip,rk3568-qos", "syscon";
        reg = <0x00000000 0xfe190000 0x00000000 0x00000020>;
        phandle = <0x0000003d>;
    };
    qos@fe190280 {
        compatible = "rockchip,rk3568-qos", "syscon";
        reg = <0x00000000 0xfe190280 0x00000000 0x00000020>;
        phandle = <0x00000041>;
    };
    qos@fe190300 {
        compatible = "rockchip,rk3568-qos", "syscon";
        reg = <0x00000000 0xfe190300 0x00000000 0x00000020>;
        phandle = <0x00000042>;
    };
    qos@fe190380 {
        compatible = "rockchip,rk3568-qos", "syscon";
        reg = <0x00000000 0xfe190380 0x00000000 0x00000020>;
        phandle = <0x00000043>;
    };
    qos@fe190400 {
        compatible = "rockchip,rk3568-qos", "syscon";
        reg = <0x00000000 0xfe190400 0x00000000 0x00000020>;
        phandle = <0x00000044>;
    };
    qos@fe198000 {
        compatible = "rockchip,rk3568-qos", "syscon";
        reg = <0x00000000 0xfe198000 0x00000000 0x00000020>;
        phandle = <0x00000039>;
    };
    qos@fe1a8000 {
        compatible = "rockchip,rk3568-qos", "syscon";
        reg = <0x00000000 0xfe1a8000 0x00000000 0x00000020>;
        phandle = <0x0000002f>;
    };
    qos@fe1a8080 {
        compatible = "rockchip,rk3568-qos", "syscon";
        reg = <0x00000000 0xfe1a8080 0x00000000 0x00000020>;
        phandle = <0x00000030>;
    };
    qos@fe1a8100 {
        compatible = "rockchip,rk3568-qos", "syscon";
        reg = <0x00000000 0xfe1a8100 0x00000000 0x00000020>;
        phandle = <0x00000031>;
    };
    pcie@fe260000 {
        compatible = "rockchip,rk3568-pcie";
        reg = <0x00000003 0xc0000000 0x00000000 0x00400000 0x00000000 0xfe260000 0x00000000 0x00010000 0x00000000 0xf4000000 0x00000000 0x00100000>;
        reg-names = "dbi", "apb", "config";
        interrupts = <0x00000000 0x0000004b 0x00000004 0x00000000 0x0000004a 0x00000004 0x00000000 0x00000049 0x00000004 0x00000000 0x00000048 0x00000004 0x00000000 0x00000047 0x00000004>;
        interrupt-names = "sys", "pmc", "msg", "legacy", "err";
        bus-range = <0x00000000 0x0000000f>;
        clocks = <0x0000000e 0x00000081 0x0000000e 0x00000082 0x0000000e 0x00000083 0x0000000e 0x00000084 0x0000000e 0x00000085>;
        clock-names = "aclk_mst", "aclk_slv", "aclk_dbi", "pclk", "aux";
        device_type = "pci";
        #interrupt-cells = <0x00000001>;
        interrupt-map-mask = <0x00000000 0x00000000 0x00000000 0x00000007>;
        interrupt-map = <0x00000000 0x00000000 0x00000000 0x00000001 0x00000064 0x00000000 0x00000000 0x00000000 0x00000000 0x00000002 0x00000064 0x00000001 0x00000000 0x00000000 0x00000000 0x00000003 0x00000064 0x00000002 0x00000000 0x00000000 0x00000000 0x00000004 0x00000064 0x00000003>;
        linux,pci-domain = <0x00000000>;
        num-ib-windows = <0x00000006>;
        num-ob-windows = <0x00000002>;
        max-link-speed = <0x00000002>;
        msi-map = <0x00000000 0x00000065 0x00000000 0x00001000>;
        num-lanes = <0x00000001>;
        phys = <0x00000011 0x00000002>;
        phy-names = "pcie-phy";
        power-domains = <0x00000010 0x0000000f>;
        ranges = <0x01000000 0x00000000 0xf4100000 0x00000000 0xf4100000 0x00000000 0x00100000 0x02000000 0x00000000 0xf4200000 0x00000000 0xf4200000 0x00000000 0x01e00000 0x03000000 0x00000000 0x40000000 0x00000003 0x00000000 0x00000000 0x40000000>;
        resets = <0x0000000e 0x000000a1>;
        reset-names = "pipe";
        #address-cells = <0x00000003>;
        #size-cells = <0x00000002>;
        status = "okay";
        reset-gpios = <0x00000066 0x0000001e 0x00000000>;
        vpcie3v3-supply = <0x00000067>;
        legacy-interrupt-controller {
            #address-cells = <0x00000000>;
            #interrupt-cells = <0x00000001>;
            interrupt-controller;
            interrupt-parent = <0x00000001>;
            interrupts = <0x00000000 0x00000048 0x00000001>;
            phandle = <0x00000064>;
        };
    };
    mmc@fe2b0000 {
        compatible = "rockchip,rk3568-dw-mshc", "rockchip,rk3288-dw-mshc";
        reg = <0x00000000 0xfe2b0000 0x00000000 0x00004000>;
        interrupts = <0x00000000 0x00000062 0x00000004>;
        clocks = <0x0000000e 0x000000b0 0x0000000e 0x000000b1 0x0000000e 0x0000018a 0x0000000e 0x0000018b>;
        clock-names = "biu", "ciu", "ciu-drive", "ciu-sample";
        fifo-depth = <0x00000100>;
        max-frequency = <0x08f0d180>;
        resets = <0x0000000e 0x000000d4>;
        reset-names = "reset";
        status = "okay";
        bus-width = <0x00000004>;
        cap-sd-highspeed;
        cd-gpios = <0x00000021 0x00000004 0x00000001>;
        disable-wp;
        pinctrl-names = "default";
        pinctrl-0 = <0x00000068 0x00000069 0x0000006a 0x0000006b>;
        sd-uhs-sdr50;
        vmmc-supply = <0x0000006c>;
        vqmmc-supply = <0x0000001a>;
    };
    mmc@fe2c0000 {
        compatible = "rockchip,rk3568-dw-mshc", "rockchip,rk3288-dw-mshc";
        reg = <0x00000000 0xfe2c0000 0x00000000 0x00004000>;
        interrupts = <0x00000000 0x00000063 0x00000004>;
        clocks = <0x0000000e 0x000000b2 0x0000000e 0x000000b3 0x0000000e 0x0000018c 0x0000000e 0x0000018d>;
        clock-names = "biu", "ciu", "ciu-drive", "ciu-sample";
        fifo-depth = <0x00000100>;
        max-frequency = <0x08f0d180>;
        resets = <0x0000000e 0x000000d6>;
        reset-names = "reset";
        status = "disabled";
    };
    spi@fe300000 {
        compatible = "rockchip,sfc";
        reg = <0x00000000 0xfe300000 0x00000000 0x00004000>;
        interrupts = <0x00000000 0x00000065 0x00000004>;
        clocks = <0x0000000e 0x00000078 0x0000000e 0x00000076>;
        clock-names = "clk_sfc", "hclk_sfc";
        pinctrl-0 = <0x0000006d>;
        pinctrl-names = "default";
        status = "disabled";
    };
    mmc@fe310000 {
        compatible = "rockchip,rk3568-dwcmshc";
        reg = <0x00000000 0xfe310000 0x00000000 0x00010000>;
        interrupts = <0x00000000 0x00000013 0x00000004>;
        assigned-clocks = <0x0000000e 0x0000007b 0x0000000e 0x0000007d>;
        assigned-clock-rates = <0x0bebc200 0x016e3600>;
        clocks = <0x0000000e 0x0000007c 0x0000000e 0x0000007a 0x0000000e 0x00000079 0x0000000e 0x0000007b 0x0000000e 0x0000007d>;
        clock-names = "core", "bus", "axi", "block", "timer";
        status = "okay";
        bus-width = <0x00000008>;
        max-frequency = <0x0bebc200>;
        non-removable;
        pinctrl-names = "default";
        pinctrl-0 = <0x0000006e 0x0000006f 0x00000070 0x00000071>;
    };
    i2s@fe400000 {
        compatible = "rockchip,rk3568-i2s-tdm";
        reg = <0x00000000 0xfe400000 0x00000000 0x00001000>;
        interrupts = <0x00000000 0x00000034 0x00000004>;
        assigned-clocks = <0x0000000e 0x0000003d 0x0000000e 0x00000041>;
        assigned-clock-rates = <0x46cf7100 0x46cf7100>;
        clocks = <0x0000000e 0x0000003f 0x0000000e 0x00000043 0x0000000e 0x00000039>;
        clock-names = "mclk_tx", "mclk_rx", "hclk";
        dmas = <0x00000072 0x00000000>;
        dma-names = "tx";
        resets = <0x0000000e 0x00000050 0x0000000e 0x00000051>;
        reset-names = "tx-m", "rx-m";
        rockchip,grf = <0x0000001e>;
        #sound-dai-cells = <0x00000000>;
        status = "okay";
        phandle = <0x00000008>;
    };
    i2s@fe410000 {
        compatible = "rockchip,rk3568-i2s-tdm";
        reg = <0x00000000 0xfe410000 0x00000000 0x00001000>;
        interrupts = <0x00000000 0x00000035 0x00000004>;
        assigned-clocks = <0x0000000e 0x00000045 0x0000000e 0x00000049>;
        assigned-clock-rates = <0x46cf7100 0x46cf7100>;
        clocks = <0x0000000e 0x00000047 0x0000000e 0x0000004b 0x0000000e 0x0000003a>;
        clock-names = "mclk_tx", "mclk_rx", "hclk";
        dmas = <0x00000072 0x00000003 0x00000072 0x00000002>;
        dma-names = "rx", "tx";
        resets = <0x0000000e 0x00000052 0x0000000e 0x00000053>;
        reset-names = "tx-m", "rx-m";
        rockchip,grf = <0x0000001e>;
        pinctrl-names = "default";
        pinctrl-0 = <0x00000073 0x00000074 0x00000075 0x00000076 0x00000077 0x00000078 0x00000079 0x0000007a 0x0000007b 0x0000007c 0x0000007d 0x0000007e>;
        #sound-dai-cells = <0x00000000>;
        status = "okay";
        rockchip,trcm-sync-tx-only;
        phandle = <0x000000e1>;
    };
    i2s@fe420000 {
        compatible = "rockchip,rk3568-i2s-tdm";
        reg = <0x00000000 0xfe420000 0x00000000 0x00001000>;
        interrupts = <0x00000000 0x00000036 0x00000004>;
        assigned-clocks = <0x0000000e 0x0000004d>;
        assigned-clock-rates = <0x46cf7100>;
        clocks = <0x0000000e 0x0000004f 0x0000000e 0x0000004f 0x0000000e 0x0000003b>;
        clock-names = "mclk_tx", "mclk_rx", "hclk";
        dmas = <0x00000072 0x00000004 0x00000072 0x00000005>;
        dma-names = "tx", "rx";
        resets = <0x0000000e 0x00000054>;
        reset-names = "tx-m";
        rockchip,grf = <0x0000001e>;
        pinctrl-names = "default";
        pinctrl-0 = <0x0000007f 0x00000080 0x00000081 0x00000082>;
        #sound-dai-cells = <0x00000000>;
        status = "disabled";
    };
    i2s@fe430000 {
        compatible = "rockchip,rk3568-i2s-tdm";
        reg = <0x00000000 0xfe430000 0x00000000 0x00001000>;
        interrupts = <0x00000000 0x00000037 0x00000004>;
        clocks = <0x0000000e 0x00000053 0x0000000e 0x00000057 0x0000000e 0x0000003c>;
        clock-names = "mclk_tx", "mclk_rx", "hclk";
        dmas = <0x00000072 0x00000006 0x00000072 0x00000007>;
        dma-names = "tx", "rx";
        resets = <0x0000000e 0x00000055 0x0000000e 0x00000056>;
        reset-names = "tx-m", "rx-m";
        rockchip,grf = <0x0000001e>;
        #sound-dai-cells = <0x00000000>;
        status = "disabled";
    };
    pdm@fe440000 {
        compatible = "rockchip,rk3568-pdm";
        reg = <0x00000000 0xfe440000 0x00000000 0x00001000>;
        interrupts = <0x00000000 0x0000004c 0x00000004>;
        clocks = <0x0000000e 0x0000005a 0x0000000e 0x00000059>;
        clock-names = "pdm_clk", "pdm_hclk";
        dmas = <0x00000072 0x00000009>;
        dma-names = "rx";
        pinctrl-0 = <0x00000083 0x00000084 0x00000085 0x00000086 0x00000087 0x00000088>;
        pinctrl-names = "default";
        resets = <0x0000000e 0x00000058>;
        reset-names = "pdm-m";
        #sound-dai-cells = <0x00000000>;
        status = "disabled";
    };
    spdif@fe460000 {
        compatible = "rockchip,rk3568-spdif";
        reg = <0x00000000 0xfe460000 0x00000000 0x00001000>;
        interrupts = <0x00000000 0x00000066 0x00000004>;
        clock-names = "mclk", "hclk";
        clocks = <0x0000000e 0x0000005f 0x0000000e 0x0000005c>;
        dmas = <0x00000072 0x00000001>;
        dma-names = "tx";
        pinctrl-names = "default";
        pinctrl-0 = <0x00000089>;
        #sound-dai-cells = <0x00000000>;
        status = "disabled";
    };
    dma-controller@fe530000 {
        compatible = "arm,pl330", "arm,primecell";
        reg = <0x00000000 0xfe530000 0x00000000 0x00004000>;
        interrupts = <0x00000000 0x0000000e 0x00000004 0x00000000 0x0000000d 0x00000004>;
        arm,pl330-periph-burst;
        clocks = <0x0000000e 0x0000010d>;
        clock-names = "apb_pclk";
        #dma-cells = <0x00000001>;
        phandle = <0x00000025>;
    };
    dma-controller@fe550000 {
        compatible = "arm,pl330", "arm,primecell";
        reg = <0x00000000 0xfe550000 0x00000000 0x00004000>;
        interrupts = <0x00000000 0x00000010 0x00000004 0x00000000 0x0000000f 0x00000004>;
        arm,pl330-periph-burst;
        clocks = <0x0000000e 0x0000010d>;
        clock-names = "apb_pclk";
        #dma-cells = <0x00000001>;
        phandle = <0x00000072>;
    };
    i2c@fe5a0000 {
        compatible = "rockchip,rk3568-i2c", "rockchip,rk3399-i2c";
        reg = <0x00000000 0xfe5a0000 0x00000000 0x00001000>;
        interrupts = <0x00000000 0x0000002f 0x00000004>;
        clocks = <0x0000000e 0x00000148 0x0000000e 0x00000147>;
        clock-names = "i2c", "pclk";
        pinctrl-0 = <0x0000008a>;
        pinctrl-names = "default";
        #address-cells = <0x00000001>;
        #size-cells = <0x00000000>;
        status = "disabled";
    };
    i2c@fe5b0000 {
        compatible = "rockchip,rk3568-i2c", "rockchip,rk3399-i2c";
        reg = <0x00000000 0xfe5b0000 0x00000000 0x00001000>;
        interrupts = <0x00000000 0x00000030 0x00000004>;
        clocks = <0x0000000e 0x0000014a 0x0000000e 0x00000149>;
        clock-names = "i2c", "pclk";
        pinctrl-0 = <0x0000008b>;
        pinctrl-names = "default";
        #address-cells = <0x00000001>;
        #size-cells = <0x00000000>;
        status = "disabled";
    };
    i2c@fe5c0000 {
        compatible = "rockchip,rk3568-i2c", "rockchip,rk3399-i2c";
        reg = <0x00000000 0xfe5c0000 0x00000000 0x00001000>;
        interrupts = <0x00000000 0x00000031 0x00000004>;
        clocks = <0x0000000e 0x0000014c 0x0000000e 0x0000014b>;
        clock-names = "i2c", "pclk";
        pinctrl-0 = <0x0000008c>;
        pinctrl-names = "default";
        #address-cells = <0x00000001>;
        #size-cells = <0x00000000>;
        status = "disabled";
    };
    i2c@fe5d0000 {
        compatible = "rockchip,rk3568-i2c", "rockchip,rk3399-i2c";
        reg = <0x00000000 0xfe5d0000 0x00000000 0x00001000>;
        interrupts = <0x00000000 0x00000032 0x00000004>;
        clocks = <0x0000000e 0x0000014e 0x0000000e 0x0000014d>;
        clock-names = "i2c", "pclk";
        pinctrl-0 = <0x0000008d>;
        pinctrl-names = "default";
        #address-cells = <0x00000001>;
        #size-cells = <0x00000000>;
        status = "disabled";
    };
    i2c@fe5e0000 {
        compatible = "rockchip,rk3568-i2c", "rockchip,rk3399-i2c";
        reg = <0x00000000 0xfe5e0000 0x00000000 0x00001000>;
        interrupts = <0x00000000 0x00000033 0x00000004>;
        clocks = <0x0000000e 0x00000150 0x0000000e 0x0000014f>;
        clock-names = "i2c", "pclk";
        pinctrl-0 = <0x0000008e>;
        pinctrl-names = "default";
        #address-cells = <0x00000001>;
        #size-cells = <0x00000000>;
        status = "okay";
    };
    watchdog@fe600000 {
        compatible = "rockchip,rk3568-wdt", "snps,dw-wdt";
        reg = <0x00000000 0xfe600000 0x00000000 0x00000100>;
        interrupts = <0x00000000 0x00000095 0x00000004>;
        clocks = <0x0000000e 0x00000116 0x0000000e 0x00000115>;
        clock-names = "tclk", "pclk";
    };
    spi@fe610000 {
        compatible = "rockchip,rk3568-spi", "rockchip,rk3066-spi";
        reg = <0x00000000 0xfe610000 0x00000000 0x00001000>;
        interrupts = <0x00000000 0x00000067 0x00000004>;
        clocks = <0x0000000e 0x00000152 0x0000000e 0x00000151>;
        clock-names = "spiclk", "apb_pclk";
        dmas = <0x00000025 0x00000014 0x00000025 0x00000015>;
        dma-names = "tx", "rx";
        pinctrl-names = "default";
        pinctrl-0 = <0x0000008f 0x00000090 0x00000091>;
        #address-cells = <0x00000001>;
        #size-cells = <0x00000000>;
        status = "disabled";
    };
    spi@fe620000 {
        compatible = "rockchip,rk3568-spi", "rockchip,rk3066-spi";
        reg = <0x00000000 0xfe620000 0x00000000 0x00001000>;
        interrupts = <0x00000000 0x00000068 0x00000004>;
        clocks = <0x0000000e 0x00000154 0x0000000e 0x00000153>;
        clock-names = "spiclk", "apb_pclk";
        dmas = <0x00000025 0x00000016 0x00000025 0x00000017>;
        dma-names = "tx", "rx";
        pinctrl-names = "default";
        pinctrl-0 = <0x00000092 0x00000093 0x00000094>;
        #address-cells = <0x00000001>;
        #size-cells = <0x00000000>;
        status = "disabled";
    };
    spi@fe630000 {
        compatible = "rockchip,rk3568-spi", "rockchip,rk3066-spi";
        reg = <0x00000000 0xfe630000 0x00000000 0x00001000>;
        interrupts = <0x00000000 0x00000069 0x00000004>;
        clocks = <0x0000000e 0x00000156 0x0000000e 0x00000155>;
        clock-names = "spiclk", "apb_pclk";
        dmas = <0x00000025 0x00000018 0x00000025 0x00000019>;
        dma-names = "tx", "rx";
        pinctrl-names = "default";
        pinctrl-0 = <0x00000095 0x00000096 0x00000097>;
        #address-cells = <0x00000001>;
        #size-cells = <0x00000000>;
        status = "disabled";
    };
    spi@fe640000 {
        compatible = "rockchip,rk3568-spi", "rockchip,rk3066-spi";
        reg = <0x00000000 0xfe640000 0x00000000 0x00001000>;
        interrupts = <0x00000000 0x0000006a 0x00000004>;
        clocks = <0x0000000e 0x00000158 0x0000000e 0x00000157>;
        clock-names = "spiclk", "apb_pclk";
        dmas = <0x00000025 0x0000001a 0x00000025 0x0000001b>;
        dma-names = "tx", "rx";
        pinctrl-names = "default";
        pinctrl-0 = <0x00000098 0x00000099 0x0000009a>;
        #address-cells = <0x00000001>;
        #size-cells = <0x00000000>;
        status = "disabled";
    };
    serial@fe650000 {
        compatible = "rockchip,rk3568-uart", "snps,dw-apb-uart";
        reg = <0x00000000 0xfe650000 0x00000000 0x00000100>;
        interrupts = <0x00000000 0x00000075 0x00000004>;
        clocks = <0x0000000e 0x0000011f 0x0000000e 0x0000011c>;
        clock-names = "baudclk", "apb_pclk";
        dmas = <0x00000025 0x00000002 0x00000025 0x00000003>;
        pinctrl-0 = <0x0000009b>;
        pinctrl-names = "default";
        reg-io-width = <0x00000004>;
        reg-shift = <0x00000002>;
        status = "disabled";
    };
    serial@fe660000 {
        compatible = "rockchip,rk3568-uart", "snps,dw-apb-uart";
        reg = <0x00000000 0xfe660000 0x00000000 0x00000100>;
        interrupts = <0x00000000 0x00000076 0x00000004>;
        clocks = <0x0000000e 0x00000123 0x0000000e 0x00000120>;
        clock-names = "baudclk", "apb_pclk";
        dmas = <0x00000025 0x00000004 0x00000025 0x00000005>;
        pinctrl-0 = <0x0000009c>;
        pinctrl-names = "default";
        reg-io-width = <0x00000004>;
        reg-shift = <0x00000002>;
        status = "okay";
    };
    serial@fe670000 {
        compatible = "rockchip,rk3568-uart", "snps,dw-apb-uart";
        reg = <0x00000000 0xfe670000 0x00000000 0x00000100>;
        interrupts = <0x00000000 0x00000077 0x00000004>;
        clocks = <0x0000000e 0x00000127 0x0000000e 0x00000124>;
        clock-names = "baudclk", "apb_pclk";
        dmas = <0x00000025 0x00000006 0x00000025 0x00000007>;
        pinctrl-0 = <0x0000009d>;
        pinctrl-names = "default";
        reg-io-width = <0x00000004>;
        reg-shift = <0x00000002>;
        status = "disabled";
    };
    serial@fe680000 {
        compatible = "rockchip,rk3568-uart", "snps,dw-apb-uart";
        reg = <0x00000000 0xfe680000 0x00000000 0x00000100>;
        interrupts = <0x00000000 0x00000078 0x00000004>;
        clocks = <0x0000000e 0x0000012b 0x0000000e 0x00000128>;
        clock-names = "baudclk", "apb_pclk";
        dmas = <0x00000025 0x00000008 0x00000025 0x00000009>;
        pinctrl-0 = <0x0000009e>;
        pinctrl-names = "default";
        reg-io-width = <0x00000004>;
        reg-shift = <0x00000002>;
        status = "disabled";
    };
    serial@fe690000 {
        compatible = "rockchip,rk3568-uart", "snps,dw-apb-uart";
        reg = <0x00000000 0xfe690000 0x00000000 0x00000100>;
        interrupts = <0x00000000 0x00000079 0x00000004>;
        clocks = <0x0000000e 0x0000012f 0x0000000e 0x0000012c>;
        clock-names = "baudclk", "apb_pclk";
        dmas = <0x00000025 0x0000000a 0x00000025 0x0000000b>;
        pinctrl-0 = <0x0000009f>;
        pinctrl-names = "default";
        reg-io-width = <0x00000004>;
        reg-shift = <0x00000002>;
        status = "disabled";
    };
    serial@fe6a0000 {
        compatible = "rockchip,rk3568-uart", "snps,dw-apb-uart";
        reg = <0x00000000 0xfe6a0000 0x00000000 0x00000100>;
        interrupts = <0x00000000 0x0000007a 0x00000004>;
        clocks = <0x0000000e 0x00000133 0x0000000e 0x00000130>;
        clock-names = "baudclk", "apb_pclk";
        dmas = <0x00000025 0x0000000c 0x00000025 0x0000000d>;
        pinctrl-0 = <0x000000a0>;
        pinctrl-names = "default";
        reg-io-width = <0x00000004>;
        reg-shift = <0x00000002>;
        status = "disabled";
    };
    serial@fe6b0000 {
        compatible = "rockchip,rk3568-uart", "snps,dw-apb-uart";
        reg = <0x00000000 0xfe6b0000 0x00000000 0x00000100>;
        interrupts = <0x00000000 0x0000007b 0x00000004>;
        clocks = <0x0000000e 0x00000137 0x0000000e 0x00000134>;
        clock-names = "baudclk", "apb_pclk";
        dmas = <0x00000025 0x0000000e 0x00000025 0x0000000f>;
        pinctrl-0 = <0x000000a1>;
        pinctrl-names = "default";
        reg-io-width = <0x00000004>;
        reg-shift = <0x00000002>;
        status = "disabled";
    };
    serial@fe6c0000 {
        compatible = "rockchip,rk3568-uart", "snps,dw-apb-uart";
        reg = <0x00000000 0xfe6c0000 0x00000000 0x00000100>;
        interrupts = <0x00000000 0x0000007c 0x00000004>;
        clocks = <0x0000000e 0x0000013b 0x0000000e 0x00000138>;
        clock-names = "baudclk", "apb_pclk";
        dmas = <0x00000025 0x00000010 0x00000025 0x00000011>;
        pinctrl-0 = <0x000000a2>;
        pinctrl-names = "default";
        reg-io-width = <0x00000004>;
        reg-shift = <0x00000002>;
        status = "disabled";
    };
    serial@fe6d0000 {
        compatible = "rockchip,rk3568-uart", "snps,dw-apb-uart";
        reg = <0x00000000 0xfe6d0000 0x00000000 0x00000100>;
        interrupts = <0x00000000 0x0000007d 0x00000004>;
        clocks = <0x0000000e 0x0000013f 0x0000000e 0x0000013c>;
        clock-names = "baudclk", "apb_pclk";
        dmas = <0x00000025 0x00000012 0x00000025 0x00000013>;
        pinctrl-0 = <0x000000a3>;
        pinctrl-names = "default";
        reg-io-width = <0x00000004>;
        reg-shift = <0x00000002>;
        status = "disabled";
    };
    thermal-zones {
        cpu-thermal {
            polling-delay-passive = <0x00000064>;
            polling-delay = <0x000003e8>;
            thermal-sensors = <0x000000a4 0x00000000>;
            trips {
                cpu_alert0 {
                    temperature = <0x00011170>;
                    hysteresis = <0x000007d0>;
                    type = "passive";
                    phandle = <0x000000a5>;
                };
                cpu_alert1 {
                    temperature = <0x000124f8>;
                    hysteresis = <0x000007d0>;
                    type = "passive";
                };
                cpu_crit {
                    temperature = <0x00017318>;
                    hysteresis = <0x000007d0>;
                    type = "critical";
                };
                cpu_low {
                    temperature = <0x00009c40>;
                    hysteresis = <0x000007d0>;
                    type = "active";
                    phandle = <0x000000a6>;
                };
                cpu_passive {
                    temperature = <0x0000a028>;
                    hysteresis = <0x000007d0>;
                    type = "active";
                    phandle = <0x000000a8>;
                };
                cpu_active {
                    temperature = <0x0000e678>;
                    hysteresis = <0x000007d0>;
                    type = "active";
                    phandle = <0x000000a9>;
                };
                cpu_warm {
                    temperature = <0x0000fde8>;
                    hysteresis = <0x000007d0>;
                    type = "active";
                    phandle = <0x000000aa>;
                };
                cpu_hot {
                    temperature = <0x00011170>;
                    hysteresis = <0x000007d0>;
                    type = "active";
                    phandle = <0x000000ab>;
                };
            };
            cooling-maps {
                map0 {
                    trip = <0x000000a5>;
                    cooling-device = <0x00000009 0xffffffff 0xffffffff 0x0000000a 0xffffffff 0xffffffff 0x0000000b 0xffffffff 0xffffffff 0x0000000c 0xffffffff 0xffffffff>;
                };
                map1 {
                    trip = <0x000000a6>;
                    cooling-device = <0x000000a7 0x00000000 0x00000000>;
                };
                map2 {
                    trip = <0x000000a8>;
                    cooling-device = <0x000000a7 0x00000001 0x00000001>;
                };
                map3 {
                    trip = <0x000000a9>;
                    cooling-device = <0x000000a7 0x00000002 0x00000002>;
                };
                map4 {
                    trip = <0x000000a9>;
                    cooling-device = <0x000000a7 0x00000003 0x00000003>;
                };
                map5 {
                    trip = <0x000000a9>;
                    cooling-device = <0x000000a7 0x00000004 0x00000004>;
                };
                map6 {
                    trip = <0x000000a9>;
                    cooling-device = <0x000000a7 0x00000005 0x00000005>;
                };
                map7 {
                    trip = <0x000000a9>;
                    cooling-device = <0x000000a7 0x00000006 0x00000006>;
                };
                map8 {
                    trip = <0x000000aa>;
                    cooling-device = <0x000000a7 0x00000007 0x00000007>;
                };
                map9 {
                    trip = <0x000000aa>;
                    cooling-device = <0x000000a7 0x00000008 0x00000008>;
                };
                map10 {
                    trip = <0x000000ab>;
                    cooling-device = <0x000000a7 0x00000009 0x00000009>;
                };
            };
        };
        gpu-thermal {
            polling-delay-passive = <0x00000014>;
            polling-delay = <0x000003e8>;
            thermal-sensors = <0x000000a4 0x00000001>;
            trips {
                gpu-threshold {
                    temperature = <0x00011170>;
                    hysteresis = <0x000007d0>;
                    type = "passive";
                };
                gpu-target {
                    temperature = <0x000124f8>;
                    hysteresis = <0x000007d0>;
                    type = "passive";
                    phandle = <0x000000ac>;
                };
                gpu-crit {
                    temperature = <0x00017318>;
                    hysteresis = <0x000007d0>;
                    type = "critical";
                };
            };
            cooling-maps {
                map0 {
                    trip = <0x000000ac>;
                    cooling-device = <0x000000ad 0xffffffff 0xffffffff>;
                };
            };
        };
    };
    tsadc@fe710000 {
        compatible = "rockchip,rk3568-tsadc";
        reg = <0x00000000 0xfe710000 0x00000000 0x00000100>;
        interrupts = <0x00000000 0x00000073 0x00000004>;
        assigned-clocks = <0x0000000e 0x00000110 0x0000000e 0x00000111>;
        assigned-clock-rates = <0x01036640 0x000aae60>;
        clocks = <0x0000000e 0x00000111 0x0000000e 0x0000010f>;
        clock-names = "tsadc", "apb_pclk";
        resets = <0x0000000e 0x00000181 0x0000000e 0x00000182 0x0000000e 0x000001d7>;
        rockchip,grf = <0x0000001e>;
        rockchip,hw-tshut-temp = <0x00017318>;
        pinctrl-names = "init", "default", "sleep";
        pinctrl-0 = <0x000000ae>;
        pinctrl-1 = <0x000000af>;
        pinctrl-2 = <0x000000ae>;
        #thermal-sensor-cells = <0x00000001>;
        status = "okay";
        rockchip,hw-tshut-mode = <0x00000000>;
        rockchip,hw-tshut-polarity = <0x00000000>;
        phandle = <0x000000a4>;
    };
    saradc@fe720000 {
        compatible = "rockchip,rk3568-saradc", "rockchip,rk3399-saradc";
        reg = <0x00000000 0xfe720000 0x00000000 0x00000100>;
        interrupts = <0x00000000 0x0000005d 0x00000004>;
        clocks = <0x0000000e 0x00000113 0x0000000e 0x00000112>;
        clock-names = "saradc", "apb_pclk";
        resets = <0x0000000e 0x00000180>;
        reset-names = "saradc-apb";
        #io-channel-cells = <0x00000001>;
        status = "okay";
        vref-supply = <0x000000b0>;
    };
    pwm@fe6e0000 {
        compatible = "rockchip,rk3568-pwm", "rockchip,rk3328-pwm";
        reg = <0x00000000 0xfe6e0000 0x00000000 0x00000010>;
        clocks = <0x0000000e 0x0000015a 0x0000000e 0x00000159>;
        clock-names = "pwm", "pclk";
        pinctrl-0 = <0x000000b1>;
        pinctrl-names = "default";
        #pwm-cells = <0x00000003>;
        status = "disabled";
    };
    pwm@fe6e0010 {
        compatible = "rockchip,rk3568-pwm", "rockchip,rk3328-pwm";
        reg = <0x00000000 0xfe6e0010 0x00000000 0x00000010>;
        clocks = <0x0000000e 0x0000015a 0x0000000e 0x00000159>;
        clock-names = "pwm", "pclk";
        pinctrl-0 = <0x000000b2>;
        pinctrl-names = "default";
        #pwm-cells = <0x00000003>;
        status = "disabled";
    };
    pwm@fe6e0020 {
        compatible = "rockchip,rk3568-pwm", "rockchip,rk3328-pwm";
        reg = <0x00000000 0xfe6e0020 0x00000000 0x00000010>;
        clocks = <0x0000000e 0x0000015a 0x0000000e 0x00000159>;
        clock-names = "pwm", "pclk";
        pinctrl-0 = <0x000000b3>;
        pinctrl-names = "default";
        #pwm-cells = <0x00000003>;
        status = "disabled";
    };
    pwm@fe6e0030 {
        compatible = "rockchip,rk3568-pwm", "rockchip,rk3328-pwm";
        reg = <0x00000000 0xfe6e0030 0x00000000 0x00000010>;
        clocks = <0x0000000e 0x0000015a 0x0000000e 0x00000159>;
        clock-names = "pwm", "pclk";
        pinctrl-0 = <0x000000b4>;
        pinctrl-names = "default";
        #pwm-cells = <0x00000003>;
        status = "disabled";
    };
    pwm@fe6f0000 {
        compatible = "rockchip,rk3568-pwm", "rockchip,rk3328-pwm";
        reg = <0x00000000 0xfe6f0000 0x00000000 0x00000010>;
        clocks = <0x0000000e 0x0000015d 0x0000000e 0x0000015c>;
        clock-names = "pwm", "pclk";
        pinctrl-0 = <0x000000b5>;
        pinctrl-names = "default";
        #pwm-cells = <0x00000003>;
        status = "disabled";
    };
    pwm@fe6f0010 {
        compatible = "rockchip,rk3568-pwm", "rockchip,rk3328-pwm";
        reg = <0x00000000 0xfe6f0010 0x00000000 0x00000010>;
        clocks = <0x0000000e 0x0000015d 0x0000000e 0x0000015c>;
        clock-names = "pwm", "pclk";
        pinctrl-0 = <0x000000b6>;
        pinctrl-names = "default";
        #pwm-cells = <0x00000003>;
        status = "disabled";
    };
    pwm@fe6f0020 {
        compatible = "rockchip,rk3568-pwm", "rockchip,rk3328-pwm";
        reg = <0x00000000 0xfe6f0020 0x00000000 0x00000010>;
        clocks = <0x0000000e 0x0000015d 0x0000000e 0x0000015c>;
        clock-names = "pwm", "pclk";
        pinctrl-0 = <0x000000b7>;
        pinctrl-names = "default";
        #pwm-cells = <0x00000003>;
        status = "disabled";
    };
    pwm@fe6f0030 {
        compatible = "rockchip,rk3568-pwm", "rockchip,rk3328-pwm";
        reg = <0x00000000 0xfe6f0030 0x00000000 0x00000010>;
        clocks = <0x0000000e 0x0000015d 0x0000000e 0x0000015c>;
        clock-names = "pwm", "pclk";
        pinctrl-0 = <0x000000b8>;
        pinctrl-names = "default";
        #pwm-cells = <0x00000003>;
        status = "disabled";
    };
    pwm@fe700000 {
        compatible = "rockchip,rk3568-pwm", "rockchip,rk3328-pwm";
        reg = <0x00000000 0xfe700000 0x00000000 0x00000010>;
        clocks = <0x0000000e 0x00000160 0x0000000e 0x0000015f>;
        clock-names = "pwm", "pclk";
        pinctrl-0 = <0x000000b9>;
        pinctrl-names = "default";
        #pwm-cells = <0x00000003>;
        status = "disabled";
    };
    pwm@fe700010 {
        compatible = "rockchip,rk3568-pwm", "rockchip,rk3328-pwm";
        reg = <0x00000000 0xfe700010 0x00000000 0x00000010>;
        clocks = <0x0000000e 0x00000160 0x0000000e 0x0000015f>;
        clock-names = "pwm", "pclk";
        pinctrl-0 = <0x000000ba>;
        pinctrl-names = "default";
        #pwm-cells = <0x00000003>;
        status = "disabled";
    };
    pwm@fe700020 {
        compatible = "rockchip,rk3568-pwm", "rockchip,rk3328-pwm";
        reg = <0x00000000 0xfe700020 0x00000000 0x00000010>;
        clocks = <0x0000000e 0x00000160 0x0000000e 0x0000015f>;
        clock-names = "pwm", "pclk";
        pinctrl-0 = <0x000000bb>;
        pinctrl-names = "default";
        #pwm-cells = <0x00000003>;
        status = "disabled";
    };
    pwm@fe700030 {
        compatible = "rockchip,rk3568-pwm", "rockchip,rk3328-pwm";
        reg = <0x00000000 0xfe700030 0x00000000 0x00000010>;
        clocks = <0x0000000e 0x00000160 0x0000000e 0x0000015f>;
        clock-names = "pwm", "pclk";
        pinctrl-0 = <0x000000bc>;
        pinctrl-names = "default";
        #pwm-cells = <0x00000003>;
        status = "disabled";
    };
    phy@fe830000 {
        compatible = "rockchip,rk3568-naneng-combphy";
        reg = <0x00000000 0xfe830000 0x00000000 0x00000100>;
        clocks = <0x0000001d 0x00000022 0x0000000e 0x0000017d 0x0000000e 0x0000007f>;
        clock-names = "ref", "apb", "pipe";
        assigned-clocks = <0x0000001d 0x00000022>;
        assigned-clock-rates = <0x05f5e100>;
        resets = <0x0000000e 0x000001c7>;
        reset-names = "phy";
        rockchip,pipe-grf = <0x000000bd>;
        rockchip,pipe-phy-grf = <0x000000be>;
        #phy-cells = <0x00000001>;
        status = "okay";
        phandle = <0x0000000f>;
    };
    phy@fe840000 {
        compatible = "rockchip,rk3568-naneng-combphy";
        reg = <0x00000000 0xfe840000 0x00000000 0x00000100>;
        clocks = <0x0000001d 0x00000025 0x0000000e 0x0000017e 0x0000000e 0x0000007f>;
        clock-names = "ref", "apb", "pipe";
        assigned-clocks = <0x0000001d 0x00000025>;
        assigned-clock-rates = <0x05f5e100>;
        resets = <0x0000000e 0x000001c9>;
        reset-names = "phy";
        rockchip,pipe-grf = <0x000000bd>;
        rockchip,pipe-phy-grf = <0x000000bf>;
        #phy-cells = <0x00000001>;
        status = "okay";
        phandle = <0x00000011>;
    };
    phy@fe870000 {
        compatible = "rockchip,rk3568-csi-dphy";
        reg = <0x00000000 0xfe870000 0x00000000 0x00010000>;
        clocks = <0x0000000e 0x00000179>;
        clock-names = "pclk";
        #phy-cells = <0x00000000>;
        resets = <0x0000000e 0x000001ba>;
        reset-names = "apb";
        rockchip,grf = <0x0000001e>;
        status = "disabled";
    };
    mipi-dphy@fe850000 {
        compatible = "rockchip,rk3568-dsi-dphy";
        reg = <0x00000000 0xfe850000 0x00000000 0x00010000>;
        clock-names = "ref", "pclk";
        clocks = <0x0000001d 0x00000017 0x0000000e 0x0000017a>;
        #phy-cells = <0x00000000>;
        power-domains = <0x00000010 0x00000009>;
        reset-names = "apb";
        resets = <0x0000000e 0x000001bb>;
        status = "disabled";
        phandle = <0x0000005b>;
    };
    mipi-dphy@fe860000 {
        compatible = "rockchip,rk3568-dsi-dphy";
        reg = <0x00000000 0xfe860000 0x00000000 0x00010000>;
        clock-names = "ref", "pclk";
        clocks = <0x0000001d 0x00000019 0x0000000e 0x0000017b>;
        #phy-cells = <0x00000000>;
        power-domains = <0x00000010 0x00000009>;
        reset-names = "apb";
        resets = <0x0000000e 0x000001bc>;
        status = "disabled";
        phandle = <0x0000005c>;
    };
    usb2phy@fe8a0000 {
        compatible = "rockchip,rk3568-usb2phy";
        reg = <0x00000000 0xfe8a0000 0x00000000 0x00010000>;
        clocks = <0x0000001d 0x00000013>;
        clock-names = "phyclk";
        clock-output-names = "clk_usbphy0_480m";
        interrupts = <0x00000000 0x00000087 0x00000004>;
        rockchip,usbgrf = <0x000000c0>;
        #clock-cells = <0x00000000>;
        status = "okay";
        host-port {
            #phy-cells = <0x00000000>;
            status = "okay";
            phy-supply = <0x000000c1>;
            phandle = <0x00000014>;
        };
        otg-port {
            #phy-cells = <0x00000000>;
            status = "disabled";
            phandle = <0x00000012>;
        };
    };
    usb2phy@fe8b0000 {
        compatible = "rockchip,rk3568-usb2phy";
        reg = <0x00000000 0xfe8b0000 0x00000000 0x00010000>;
        clocks = <0x0000001d 0x00000015>;
        clock-names = "phyclk";
        clock-output-names = "clk_usbphy1_480m";
        interrupts = <0x00000000 0x00000088 0x00000004>;
        rockchip,usbgrf = <0x000000c2>;
        #clock-cells = <0x00000000>;
        status = "okay";
        host-port {
            #phy-cells = <0x00000000>;
            status = "okay";
            phy-supply = <0x000000c1>;
            phandle = <0x00000016>;
        };
        otg-port {
            #phy-cells = <0x00000000>;
            status = "okay";
            phy-supply = <0x000000c1>;
            phandle = <0x00000015>;
        };
    };
    pinctrl {
        compatible = "rockchip,rk3568-pinctrl";
        rockchip,grf = <0x0000001e>;
        rockchip,pmu = <0x000000c3>;
        #address-cells = <0x00000002>;
        #size-cells = <0x00000002>;
        ranges;
        phandle = <0x000000c4>;
        gpio@fdd60000 {
            compatible = "rockchip,gpio-bank";
            reg = <0x00000000 0xfdd60000 0x00000000 0x00000100>;
            interrupts = <0x00000000 0x00000021 0x00000004>;
            clocks = <0x0000001d 0x0000002e 0x0000001d 0x0000000c>;
            gpio-controller;
            gpio-ranges = <0x000000c4 0x00000000 0x00000000 0x00000020>;
            #gpio-cells = <0x00000002>;
            interrupt-controller;
            #interrupt-cells = <0x00000002>;
            phandle = <0x00000021>;
        };
        gpio@fe740000 {
            compatible = "rockchip,gpio-bank";
            reg = <0x00000000 0xfe740000 0x00000000 0x00000100>;
            interrupts = <0x00000000 0x00000022 0x00000004>;
            clocks = <0x0000000e 0x00000163 0x0000000e 0x00000164>;
            gpio-controller;
            gpio-ranges = <0x000000c4 0x00000000 0x00000020 0x00000020>;
            #gpio-cells = <0x00000002>;
            interrupt-controller;
            #interrupt-cells = <0x00000002>;
            phandle = <0x00000057>;
        };
        gpio@fe750000 {
            compatible = "rockchip,gpio-bank";
            reg = <0x00000000 0xfe750000 0x00000000 0x00000100>;
            interrupts = <0x00000000 0x00000023 0x00000004>;
            clocks = <0x0000000e 0x00000165 0x0000000e 0x00000166>;
            gpio-controller;
            gpio-ranges = <0x000000c4 0x00000000 0x00000040 0x00000020>;
            #gpio-cells = <0x00000002>;
            interrupt-controller;
            #interrupt-cells = <0x00000002>;
            phandle = <0x00000066>;
        };
        gpio@fe760000 {
            compatible = "rockchip,gpio-bank";
            reg = <0x00000000 0xfe760000 0x00000000 0x00000100>;
            interrupts = <0x00000000 0x00000024 0x00000004>;
            clocks = <0x0000000e 0x00000167 0x0000000e 0x00000168>;
            gpio-controller;
            gpio-ranges = <0x000000c4 0x00000000 0x00000060 0x00000020>;
            #gpio-cells = <0x00000002>;
            interrupt-controller;
            #interrupt-cells = <0x00000002>;
            phandle = <0x0000004d>;
        };
        gpio@fe770000 {
            compatible = "rockchip,gpio-bank";
            reg = <0x00000000 0xfe770000 0x00000000 0x00000100>;
            interrupts = <0x00000000 0x00000025 0x00000004>;
            clocks = <0x0000000e 0x00000169 0x0000000e 0x0000016a>;
            gpio-controller;
            gpio-ranges = <0x000000c4 0x00000000 0x00000080 0x00000020>;
            #gpio-cells = <0x00000002>;
            interrupt-controller;
            #interrupt-cells = <0x00000002>;
        };
        pcfg-pull-up {
            bias-pull-up;
            phandle = <0x000000c7>;
        };
        pcfg-pull-down {
            bias-pull-down;
            phandle = <0x000000cd>;
        };
        pcfg-pull-none {
            bias-disable;
            phandle = <0x000000c5>;
        };
        pcfg-pull-none-drv-level-1 {
            bias-disable;
            drive-strength = <0x00000001>;
            phandle = <0x000000c9>;
        };
        pcfg-pull-none-drv-level-2 {
            bias-disable;
            drive-strength = <0x00000002>;
            phandle = <0x000000c8>;
        };
        pcfg-pull-none-drv-level-3 {
            bias-disable;
            drive-strength = <0x00000003>;
            phandle = <0x000000cc>;
        };
        pcfg-pull-up-drv-level-1 {
            bias-pull-up;
            drive-strength = <0x00000001>;
            phandle = <0x000000cb>;
        };
        pcfg-pull-up-drv-level-2 {
            bias-pull-up;
            drive-strength = <0x00000002>;
            phandle = <0x000000c6>;
        };
        pcfg-pull-none-smt {
            bias-disable;
            input-schmitt-enable;
            phandle = <0x000000ca>;
        };
        acodec {
        };
        audiopwm {
        };
        bt656 {
        };
        bt1120 {
        };
        cam {
        };
        can0 {
        };
        can1 {
        };
        can2 {
        };
        cif {
        };
        clk32k {
            clk32k-out0 {
                rockchip,pins = <0x00000000 0x00000008 0x00000002 0x000000c5>;
                phandle = <0x0000000d>;
            };
        };
        cpu {
        };
        ebc {
        };
        edpdp {
        };
        emmc {
            emmc-bus8 {
                rockchip,pins = <0x00000001 0x0000000c 0x00000001 0x000000c6 0x00000001 0x0000000d 0x00000001 0x000000c6 0x00000001 0x0000000e 0x00000001 0x000000c6 0x00000001 0x0000000f 0x00000001 0x000000c6 0x00000001 0x00000010 0x00000001 0x000000c6 0x00000001 0x00000011 0x00000001 0x000000c6 0x00000001 0x00000012 0x00000001 0x000000c6 0x00000001 0x00000013 0x00000001 0x000000c6>;
                phandle = <0x0000006e>;
            };
            emmc-clk {
                rockchip,pins = <0x00000001 0x00000015 0x00000001 0x000000c6>;
                phandle = <0x0000006f>;
            };
            emmc-cmd {
                rockchip,pins = <0x00000001 0x00000014 0x00000001 0x000000c6>;
                phandle = <0x00000070>;
            };
            emmc-datastrobe {
                rockchip,pins = <0x00000001 0x00000016 0x00000001 0x000000c5>;
                phandle = <0x00000071>;
            };
        };
        eth0 {
        };
        eth1 {
        };
        flash {
        };
        fspi {
            fspi-pins {
                rockchip,pins = <0x00000001 0x00000018 0x00000001 0x000000c5 0x00000001 0x0000001b 0x00000001 0x000000c5 0x00000001 0x00000019 0x00000001 0x000000c5 0x00000001 0x0000001a 0x00000001 0x000000c5 0x00000001 0x00000017 0x00000002 0x000000c5 0x00000001 0x0000001c 0x00000001 0x000000c5>;
                phandle = <0x0000006d>;
            };
        };
        gmac0 {
        };
        gmac1 {
            gmac1m1-miim {
                rockchip,pins = <0x00000004 0x0000000e 0x00000003 0x000000c5 0x00000004 0x0000000f 0x00000003 0x000000c5>;
                phandle = <0x00000052>;
            };
            gmac1m1-rx-bus2 {
                rockchip,pins = <0x00000004 0x00000007 0x00000003 0x000000c5 0x00000004 0x00000008 0x00000003 0x000000c5 0x00000004 0x00000009 0x00000003 0x000000c5>;
                phandle = <0x00000054>;
            };
            gmac1m1-tx-bus2 {
                rockchip,pins = <0x00000004 0x00000004 0x00000003 0x000000c8 0x00000004 0x00000005 0x00000003 0x000000c8 0x00000004 0x00000006 0x00000003 0x000000c5>;
                phandle = <0x00000053>;
            };
            gmac1m1-rgmii-clk {
                rockchip,pins = <0x00000004 0x00000003 0x00000003 0x000000c5 0x00000004 0x00000000 0x00000003 0x000000c9>;
                phandle = <0x00000055>;
            };
            gmac1m1-rgmii-bus {
                rockchip,pins = <0x00000004 0x00000001 0x00000003 0x000000c5 0x00000004 0x00000002 0x00000003 0x000000c5 0x00000003 0x0000001e 0x00000003 0x000000c8 0x00000003 0x0000001f 0x00000003 0x000000c8>;
                phandle = <0x00000056>;
            };
        };
        gpu {
        };
        hdmitx {
            hdmitxm0-cec {
                rockchip,pins = <0x00000004 0x00000019 0x00000001 0x000000c5>;
                phandle = <0x0000005f>;
            };
            hdmitx-scl {
                rockchip,pins = <0x00000004 0x00000017 0x00000001 0x000000c5>;
                phandle = <0x0000005d>;
            };
            hdmitx-sda {
                rockchip,pins = <0x00000004 0x00000018 0x00000001 0x000000c5>;
                phandle = <0x0000005e>;
            };
        };
        i2c0 {
            i2c0-xfer {
                rockchip,pins = <0x00000000 0x00000009 0x00000001 0x000000ca 0x00000000 0x0000000a 0x00000001 0x000000ca>;
                phandle = <0x0000001f>;
            };
        };
        i2c1 {
            i2c1-xfer {
                rockchip,pins = <0x00000000 0x0000000b 0x00000001 0x000000ca 0x00000000 0x0000000c 0x00000001 0x000000ca>;
                phandle = <0x0000008a>;
            };
        };
        i2c2 {
            i2c2m0-xfer {
                rockchip,pins = <0x00000000 0x0000000d 0x00000001 0x000000ca 0x00000000 0x0000000e 0x00000001 0x000000ca>;
                phandle = <0x0000008b>;
            };
        };
        i2c3 {
            i2c3m0-xfer {
                rockchip,pins = <0x00000001 0x00000001 0x00000001 0x000000ca 0x00000001 0x00000000 0x00000001 0x000000ca>;
                phandle = <0x0000008c>;
            };
        };
        i2c4 {
            i2c4m0-xfer {
                rockchip,pins = <0x00000004 0x0000000b 0x00000001 0x000000ca 0x00000004 0x0000000a 0x00000001 0x000000ca>;
                phandle = <0x0000008d>;
            };
        };
        i2c5 {
            i2c5m0-xfer {
                rockchip,pins = <0x00000003 0x0000000b 0x00000004 0x000000ca 0x00000003 0x0000000c 0x00000004 0x000000ca>;
                phandle = <0x0000008e>;
            };
        };
        i2s1 {
            i2s1m0-lrckrx {
                rockchip,pins = <0x00000001 0x00000006 0x00000001 0x000000c5>;
                phandle = <0x00000076>;
            };
            i2s1m0-lrcktx {
                rockchip,pins = <0x00000001 0x00000005 0x00000001 0x000000c5>;
                phandle = <0x00000075>;
            };
            i2s1m0-mclk {
                rockchip,pins = <0x00000001 0x00000002 0x00000001 0x000000c5>;
                phandle = <0x00000023>;
            };
            i2s1m0-sclkrx {
                rockchip,pins = <0x00000001 0x00000004 0x00000001 0x000000c5>;
                phandle = <0x00000074>;
            };
            i2s1m0-sclktx {
                rockchip,pins = <0x00000001 0x00000003 0x00000001 0x000000c5>;
                phandle = <0x00000073>;
            };
            i2s1m0-sdi0 {
                rockchip,pins = <0x00000001 0x0000000b 0x00000001 0x000000c5>;
                phandle = <0x00000077>;
            };
            i2s1m0-sdi1 {
                rockchip,pins = <0x00000001 0x0000000a 0x00000002 0x000000c5>;
                phandle = <0x00000078>;
            };
            i2s1m0-sdi2 {
                rockchip,pins = <0x00000001 0x00000009 0x00000002 0x000000c5>;
                phandle = <0x00000079>;
            };
            i2s1m0-sdi3 {
                rockchip,pins = <0x00000001 0x00000008 0x00000002 0x000000c5>;
                phandle = <0x0000007a>;
            };
            i2s1m0-sdo0 {
                rockchip,pins = <0x00000001 0x00000007 0x00000001 0x000000c5>;
                phandle = <0x0000007b>;
            };
            i2s1m0-sdo1 {
                rockchip,pins = <0x00000001 0x00000008 0x00000001 0x000000c5>;
                phandle = <0x0000007c>;
            };
            i2s1m0-sdo2 {
                rockchip,pins = <0x00000001 0x00000009 0x00000001 0x000000c5>;
                phandle = <0x0000007d>;
            };
            i2s1m0-sdo3 {
                rockchip,pins = <0x00000001 0x0000000a 0x00000001 0x000000c5>;
                phandle = <0x0000007e>;
            };
        };
        i2s2 {
            i2s2m0-lrcktx {
                rockchip,pins = <0x00000002 0x00000013 0x00000001 0x000000c5>;
                phandle = <0x00000080>;
            };
            i2s2m0-sclktx {
                rockchip,pins = <0x00000002 0x00000012 0x00000001 0x000000c5>;
                phandle = <0x0000007f>;
            };
            i2s2m0-sdi {
                rockchip,pins = <0x00000002 0x00000015 0x00000001 0x000000c5>;
                phandle = <0x00000081>;
            };
            i2s2m0-sdo {
                rockchip,pins = <0x00000002 0x00000014 0x00000001 0x000000c5>;
                phandle = <0x00000082>;
            };
        };
        i2s3 {
        };
        isp {
        };
        jtag {
        };
        lcdc {
        };
        mcu {
        };
        npu {
        };
        pcie20 {
        };
        pcie30x1 {
        };
        pcie30x2 {
        };
        pdm {
            pdmm0-clk {
                rockchip,pins = <0x00000001 0x00000006 0x00000003 0x000000c5>;
                phandle = <0x00000083>;
            };
            pdmm0-clk1 {
                rockchip,pins = <0x00000001 0x00000004 0x00000003 0x000000c5>;
                phandle = <0x00000084>;
            };
            pdmm0-sdi0 {
                rockchip,pins = <0x00000001 0x0000000b 0x00000002 0x000000c5>;
                phandle = <0x00000085>;
            };
            pdmm0-sdi1 {
                rockchip,pins = <0x00000001 0x0000000a 0x00000003 0x000000c5>;
                phandle = <0x00000086>;
            };
            pdmm0-sdi2 {
                rockchip,pins = <0x00000001 0x00000009 0x00000003 0x000000c5>;
                phandle = <0x00000087>;
            };
            pdmm0-sdi3 {
                rockchip,pins = <0x00000001 0x00000008 0x00000003 0x000000c5>;
                phandle = <0x00000088>;
            };
        };
        pmic {
            pmic_int {
                rockchip,pins = <0x00000000 0x00000003 0x00000000 0x000000c7>;
                phandle = <0x00000022>;
            };
        };
        pmu {
        };
        pwm0 {
            pwm0m0-pins {
                rockchip,pins = <0x00000000 0x0000000f 0x00000001 0x000000c5>;
                phandle = <0x00000027>;
            };
        };
        pwm1 {
            pwm1m0-pins {
                rockchip,pins = <0x00000000 0x00000010 0x00000001 0x000000c5>;
                phandle = <0x00000028>;
            };
        };
        pwm2 {
            pwm2m0-pins {
                rockchip,pins = <0x00000000 0x00000011 0x00000001 0x000000c5>;
                phandle = <0x00000029>;
            };
        };
        pwm3 {
            pwm3-pins {
                rockchip,pins = <0x00000000 0x00000012 0x00000001 0x000000c5>;
                phandle = <0x0000002a>;
            };
        };
        pwm4 {
            pwm4-pins {
                rockchip,pins = <0x00000000 0x00000013 0x00000001 0x000000c5>;
                phandle = <0x000000b1>;
            };
        };
        pwm5 {
            pwm5-pins {
                rockchip,pins = <0x00000000 0x00000014 0x00000001 0x000000c5>;
                phandle = <0x000000b2>;
            };
        };
        pwm6 {
            pwm6-pins {
                rockchip,pins = <0x00000000 0x00000015 0x00000001 0x000000c5>;
                phandle = <0x000000b3>;
            };
        };
        pwm7 {
            pwm7-pins {
                rockchip,pins = <0x00000000 0x00000016 0x00000001 0x000000c5>;
                phandle = <0x000000b4>;
            };
        };
        pwm8 {
            pwm8m0-pins {
                rockchip,pins = <0x00000003 0x00000009 0x00000005 0x000000c5>;
                phandle = <0x000000b5>;
            };
        };
        pwm9 {
            pwm9m0-pins {
                rockchip,pins = <0x00000003 0x0000000a 0x00000005 0x000000c5>;
                phandle = <0x000000b6>;
            };
        };
        pwm10 {
            pwm10m0-pins {
                rockchip,pins = <0x00000003 0x0000000d 0x00000005 0x000000c5>;
                phandle = <0x000000b7>;
            };
        };
        pwm11 {
            pwm11m0-pins {
                rockchip,pins = <0x00000003 0x0000000e 0x00000005 0x000000c5>;
                phandle = <0x000000b8>;
            };
        };
        pwm12 {
            pwm12m0-pins {
                rockchip,pins = <0x00000003 0x0000000f 0x00000002 0x000000c5>;
                phandle = <0x000000b9>;
            };
        };
        pwm13 {
            pwm13m0-pins {
                rockchip,pins = <0x00000003 0x00000010 0x00000002 0x000000c5>;
                phandle = <0x000000ba>;
            };
        };
        pwm14 {
            pwm14m0-pins {
                rockchip,pins = <0x00000003 0x00000014 0x00000001 0x000000c5>;
                phandle = <0x000000bb>;
            };
        };
        pwm15 {
            pwm15m0-pins {
                rockchip,pins = <0x00000003 0x00000015 0x00000001 0x000000c5>;
                phandle = <0x000000bc>;
            };
        };
        refclk {
        };
        sata {
            sata-pwr-en {
                rockchip,pins = <0x00000000 0x00000015 0x00000000 0x000000c5>;
                phandle = <0x000000e4>;
            };
        };
        sata0 {
        };
        sata1 {
        };
        sata2 {
        };
        scr {
        };
        sdmmc0 {
            sdmmc0-bus4 {
                rockchip,pins = <0x00000001 0x0000001d 0x00000001 0x000000c6 0x00000001 0x0000001e 0x00000001 0x000000c6 0x00000001 0x0000001f 0x00000001 0x000000c6 0x00000002 0x00000000 0x00000001 0x000000c6>;
                phandle = <0x00000068>;
            };
            sdmmc0-clk {
                rockchip,pins = <0x00000002 0x00000002 0x00000001 0x000000c6>;
                phandle = <0x00000069>;
            };
            sdmmc0-cmd {
                rockchip,pins = <0x00000002 0x00000001 0x00000001 0x000000c6>;
                phandle = <0x0000006a>;
            };
            sdmmc0-det {
                rockchip,pins = <0x00000000 0x00000004 0x00000001 0x000000c7>;
                phandle = <0x0000006b>;
            };
        };
        sdmmc1 {
        };
        sdmmc2 {
            sdmmc2m0-bus4 {
                rockchip,pins = <0x00000003 0x00000016 0x00000003 0x000000c6 0x00000003 0x00000017 0x00000003 0x000000c6 0x00000003 0x00000018 0x00000003 0x000000c6 0x00000003 0x00000019 0x00000003 0x000000c6>;
                phandle = <0x0000004a>;
            };
            sdmmc2m0-clk {
                rockchip,pins = <0x00000003 0x0000001b 0x00000003 0x000000c6>;
                phandle = <0x0000004c>;
            };
            sdmmc2m0-cmd {
                rockchip,pins = <0x00000003 0x0000001a 0x00000003 0x000000c6>;
                phandle = <0x0000004b>;
            };
        };
        spdif {
            spdifm0-tx {
                rockchip,pins = <0x00000001 0x00000004 0x00000004 0x000000c5>;
                phandle = <0x00000089>;
            };
        };
        spi0 {
            spi0m0-pins {
                rockchip,pins = <0x00000000 0x0000000d 0x00000002 0x000000c5 0x00000000 0x00000015 0x00000002 0x000000c5 0x00000000 0x0000000e 0x00000002 0x000000c5>;
                phandle = <0x00000091>;
            };
            spi0m0-cs0 {
                rockchip,pins = <0x00000000 0x00000016 0x00000002 0x000000c5>;
                phandle = <0x0000008f>;
            };
            spi0m0-cs1 {
                rockchip,pins = <0x00000000 0x00000014 0x00000002 0x000000c5>;
                phandle = <0x00000090>;
            };
        };
        spi1 {
            spi1m0-pins {
                rockchip,pins = <0x00000002 0x0000000d 0x00000003 0x000000c5 0x00000002 0x0000000e 0x00000003 0x000000c5 0x00000002 0x0000000f 0x00000004 0x000000c5>;
                phandle = <0x00000094>;
            };
            spi1m0-cs0 {
                rockchip,pins = <0x00000002 0x00000010 0x00000004 0x000000c5>;
                phandle = <0x00000092>;
            };
            spi1m0-cs1 {
                rockchip,pins = <0x00000002 0x00000016 0x00000003 0x000000c5>;
                phandle = <0x00000093>;
            };
        };
        spi2 {
            spi2m0-pins {
                rockchip,pins = <0x00000002 0x00000011 0x00000004 0x000000c5 0x00000002 0x00000012 0x00000004 0x000000c5 0x00000002 0x00000013 0x00000004 0x000000c5>;
                phandle = <0x00000097>;
            };
            spi2m0-cs0 {
                rockchip,pins = <0x00000002 0x00000014 0x00000004 0x000000c5>;
                phandle = <0x00000095>;
            };
            spi2m0-cs1 {
                rockchip,pins = <0x00000002 0x00000015 0x00000004 0x000000c5>;
                phandle = <0x00000096>;
            };
        };
        spi3 {
            spi3m0-pins {
                rockchip,pins = <0x00000004 0x0000000b 0x00000004 0x000000c5 0x00000004 0x00000008 0x00000004 0x000000c5 0x00000004 0x0000000a 0x00000004 0x000000c5>;
                phandle = <0x0000009a>;
            };
            spi3m0-cs0 {
                rockchip,pins = <0x00000004 0x00000006 0x00000004 0x000000c5>;
                phandle = <0x00000098>;
            };
            spi3m0-cs1 {
                rockchip,pins = <0x00000004 0x00000007 0x00000004 0x000000c5>;
                phandle = <0x00000099>;
            };
        };
        tsadc {
            tsadc-shutorg {
                rockchip,pins = <0x00000000 0x00000001 0x00000002 0x000000c5>;
                phandle = <0x000000af>;
            };
            tsadc-pin {
                rockchip,pins = <0x00000000 0x00000001 0x00000000 0x000000c5>;
                phandle = <0x000000ae>;
            };
        };
        uart0 {
            uart0-xfer {
                rockchip,pins = <0x00000000 0x00000010 0x00000003 0x000000c7 0x00000000 0x00000011 0x00000003 0x000000c7>;
                phandle = <0x00000026>;
            };
        };
        uart1 {
            uart1m0-xfer {
                rockchip,pins = <0x00000002 0x0000000b 0x00000002 0x000000c7 0x00000002 0x0000000c 0x00000002 0x000000c7>;
                phandle = <0x0000009b>;
            };
        };
        uart2 {
            uart2m0-xfer {
                rockchip,pins = <0x00000000 0x00000018 0x00000001 0x000000c7 0x00000000 0x00000019 0x00000001 0x000000c7>;
                phandle = <0x0000009c>;
            };
        };
        uart3 {
            uart3m0-xfer {
                rockchip,pins = <0x00000001 0x00000000 0x00000002 0x000000c7 0x00000001 0x00000001 0x00000002 0x000000c7>;
                phandle = <0x0000009d>;
            };
        };
        uart4 {
            uart4m0-xfer {
                rockchip,pins = <0x00000001 0x00000004 0x00000002 0x000000c7 0x00000001 0x00000006 0x00000002 0x000000c7>;
                phandle = <0x0000009e>;
            };
        };
        uart5 {
            uart5m0-xfer {
                rockchip,pins = <0x00000002 0x00000001 0x00000003 0x000000c7 0x00000002 0x00000002 0x00000003 0x000000c7>;
                phandle = <0x0000009f>;
            };
        };
        uart6 {
            uart6m0-xfer {
                rockchip,pins = <0x00000002 0x00000003 0x00000003 0x000000c7 0x00000002 0x00000004 0x00000003 0x000000c7>;
                phandle = <0x000000a0>;
            };
        };
        uart7 {
            uart7m0-xfer {
                rockchip,pins = <0x00000002 0x00000005 0x00000003 0x000000c7 0x00000002 0x00000006 0x00000003 0x000000c7>;
                phandle = <0x000000a1>;
            };
        };
        uart8 {
            uart8m0-xfer {
                rockchip,pins = <0x00000002 0x00000016 0x00000002 0x000000c7 0x00000002 0x00000015 0x00000003 0x000000c7>;
                phandle = <0x000000a2>;
            };
        };
        uart9 {
            uart9m0-xfer {
                rockchip,pins = <0x00000002 0x00000007 0x00000003 0x000000c7 0x00000002 0x00000008 0x00000003 0x000000c7>;
                phandle = <0x000000a3>;
            };
        };
        vop {
        };
        spi0-hs {
        };
        spi1-hs {
        };
        spi2-hs {
        };
        spi3-hs {
        };
        gmac-txd-level3 {
        };
        gmac-txc-level2 {
        };
        button {
            reset-button-pin {
                rockchip,pins = <0x00000000 0x00000000 0x00000000 0x000000c7>;
                phandle = <0x000000da>;
            };
        };
        leds {
            led_net_en {
                rockchip,pins = <0x00000003 0x00000005 0x00000000 0x000000c5>;
                phandle = <0x000000db>;
            };
            led_sata_en {
                rockchip,pins = <0x00000003 0x00000007 0x00000000 0x000000c5>;
                phandle = <0x000000dc>;
            };
            led_work_en {
                rockchip,pins = <0x00000003 0x00000008 0x00000000 0x000000c5>;
                phandle = <0x000000dd>;
            };
        };
        usb {
            vcc5v0_usb_host_en {
                rockchip,pins = <0x00000000 0x00000005 0x00000000 0x000000c5>;
                phandle = <0x000000df>;
            };
        };
        sdio-pwrseq {
            wifi-enable {
                rockchip,pins = <0x00000003 0x00000000 0x00000000 0x000000c5>;
                phandle = <0x000000e5>;
            };
            wifi-host-wake {
                rockchip,pins = <0x00000003 0x0000001d 0x00000000 0x000000cd>;
                phandle = <0x0000004e>;
            };
        };
    };
    sata@fc000000 {
        compatible = "rockchip,rk3568-dwc-ahci", "snps,dwc-ahci";
        reg = <0x00000000 0xfc000000 0x00000000 0x00001000>;
        clocks = <0x0000000e 0x00000096 0x0000000e 0x00000097 0x0000000e 0x00000098>;
        clock-names = "sata", "pmalive", "rxoob";
        interrupts = <0x00000000 0x0000005e 0x00000004>;
        phys = <0x00000013 0x00000001>;
        phy-names = "sata-phy";
        ports-implemented = <0x00000001>;
        power-domains = <0x00000010 0x0000000f>;
        status = "okay";
        target-supply = <0x000000ce>;
    };
    syscon@fdc70000 {
        compatible = "rockchip,rk3568-pipe-phy-grf", "syscon";
        reg = <0x00000000 0xfdc70000 0x00000000 0x00001000>;
        phandle = <0x000000d8>;
    };
    qos@fe190080 {
        compatible = "rockchip,rk3568-qos", "syscon";
        reg = <0x00000000 0xfe190080 0x00000000 0x00000020>;
        phandle = <0x0000003e>;
    };
    qos@fe190100 {
        compatible = "rockchip,rk3568-qos", "syscon";
        reg = <0x00000000 0xfe190100 0x00000000 0x00000020>;
        phandle = <0x0000003f>;
    };
    qos@fe190200 {
        compatible = "rockchip,rk3568-qos", "syscon";
        reg = <0x00000000 0xfe190200 0x00000000 0x00000020>;
        phandle = <0x00000040>;
    };
    syscon@fdcb8000 {
        compatible = "rockchip,rk3568-pcie3-phy-grf", "syscon";
        reg = <0x00000000 0xfdcb8000 0x00000000 0x00010000>;
        phandle = <0x000000cf>;
    };
    phy@fe8c0000 {
        compatible = "rockchip,rk3568-pcie3-phy";
        reg = <0x00000000 0xfe8c0000 0x00000000 0x00020000>;
        #phy-cells = <0x00000000>;
        clocks = <0x0000001d 0x00000026 0x0000001d 0x00000027 0x0000000e 0x00000177>;
        clock-names = "refclk_m", "refclk_n", "pclk";
        resets = <0x0000000e 0x000001be>;
        reset-names = "phy";
        rockchip,phy-grf = <0x000000cf>;
        status = "okay";
        data-lanes = <0x00000001 0x00000002>;
        clock-frequency = <0x05f5e100>;
        phandle = <0x000000d1>;
    };
    pcie@fe270000 {
        compatible = "rockchip,rk3568-pcie";
        #address-cells = <0x00000003>;
        #size-cells = <0x00000002>;
        bus-range = <0x00000010 0x0000001f>;
        clocks = <0x0000000e 0x00000088 0x0000000e 0x00000089 0x0000000e 0x0000008a 0x0000000e 0x0000008b 0x0000000e 0x0000008c>;
        clock-names = "aclk_mst", "aclk_slv", "aclk_dbi", "pclk", "aux";
        device_type = "pci";
        interrupts = <0x00000000 0x000000a0 0x00000004 0x00000000 0x0000009f 0x00000004 0x00000000 0x0000009e 0x00000004 0x00000000 0x0000009d 0x00000004 0x00000000 0x0000009c 0x00000004>;
        interrupt-names = "sys", "pmc", "msg", "legacy", "err";
        #interrupt-cells = <0x00000001>;
        interrupt-map-mask = <0x00000000 0x00000000 0x00000000 0x00000007>;
        interrupt-map = <0x00000000 0x00000000 0x00000000 0x00000001 0x000000d0 0x00000000 0x00000000 0x00000000 0x00000000 0x00000002 0x000000d0 0x00000001 0x00000000 0x00000000 0x00000000 0x00000003 0x000000d0 0x00000002 0x00000000 0x00000000 0x00000000 0x00000004 0x000000d0 0x00000003>;
        linux,pci-domain = <0x00000001>;
        num-ib-windows = <0x00000006>;
        num-ob-windows = <0x00000002>;
        max-link-speed = <0x00000003>;
        msi-map = <0x00001000 0x00000065 0x00001000 0x00001000>;
        num-lanes = <0x00000001>;
        phys = <0x000000d1>;
        phy-names = "pcie-phy";
        power-domains = <0x00000010 0x0000000f>;
        reg = <0x00000003 0xc0400000 0x00000000 0x00400000 0x00000000 0xfe270000 0x00000000 0x00010000 0x00000000 0xf2000000 0x00000000 0x00100000>;
        ranges = <0x01000000 0x00000000 0xf2100000 0x00000000 0xf2100000 0x00000000 0x00100000 0x02000000 0x00000000 0xf2200000 0x00000000 0xf2200000 0x00000000 0x01e00000 0x03000000 0x00000000 0x40000000 0x00000003 0x40000000 0x00000000 0x40000000>;
        reg-names = "dbi", "apb", "config";
        resets = <0x0000000e 0x000000b1>;
        reset-names = "pipe";
        status = "okay";
        reset-gpios = <0x0000004d 0x00000004 0x00000000>;
        vpcie3v3-supply = <0x000000d2>;
        legacy-interrupt-controller {
            interrupt-controller;
            #address-cells = <0x00000000>;
            #interrupt-cells = <0x00000001>;
            interrupt-parent = <0x00000001>;
            interrupts = <0x00000000 0x0000009d 0x00000001>;
            phandle = <0x000000d0>;
        };
        ethernet@11000 {
            compatible = "realtek,rtl8125", "pci10ec,8125";
            reg = <0x00011000 0x00000000 0x00000000 0x00000000 0x00000000>;
            vid = <0x000010ec>;
            pid = <0x00008125>;
            label = "board-pci-eth0";
            status = "okay";
        };
    };
    pcie@fe280000 {
        compatible = "rockchip,rk3568-pcie";
        #address-cells = <0x00000003>;
        #size-cells = <0x00000002>;
        bus-range = <0x00000020 0x0000002f>;
        clocks = <0x0000000e 0x0000008f 0x0000000e 0x00000090 0x0000000e 0x00000091 0x0000000e 0x00000092 0x0000000e 0x00000093>;
        clock-names = "aclk_mst", "aclk_slv", "aclk_dbi", "pclk", "aux";
        device_type = "pci";
        interrupts = <0x00000000 0x000000a5 0x00000004 0x00000000 0x000000a4 0x00000004 0x00000000 0x000000a3 0x00000004 0x00000000 0x000000a2 0x00000004 0x00000000 0x000000a1 0x00000004>;
        interrupt-names = "sys", "pmc", "msg", "legacy", "err";
        #interrupt-cells = <0x00000001>;
        interrupt-map-mask = <0x00000000 0x00000000 0x00000000 0x00000007>;
        interrupt-map = <0x00000000 0x00000000 0x00000000 0x00000001 0x000000d3 0x00000000 0x00000000 0x00000000 0x00000000 0x00000002 0x000000d3 0x00000001 0x00000000 0x00000000 0x00000000 0x00000003 0x000000d3 0x00000002 0x00000000 0x00000000 0x00000000 0x00000004 0x000000d3 0x00000003>;
        linux,pci-domain = <0x00000002>;
        num-ib-windows = <0x00000006>;
        num-ob-windows = <0x00000002>;
        max-link-speed = <0x00000003>;
        msi-map = <0x00002000 0x00000065 0x00002000 0x00001000>;
        num-lanes = <0x00000001>;
        phys = <0x000000d1>;
        phy-names = "pcie-phy";
        power-domains = <0x00000010 0x0000000f>;
        reg = <0x00000003 0xc0800000 0x00000000 0x00400000 0x00000000 0xfe280000 0x00000000 0x00010000 0x00000000 0xf0000000 0x00000000 0x00100000>;
        ranges = <0x01000000 0x00000000 0xf0100000 0x00000000 0xf0100000 0x00000000 0x00100000 0x02000000 0x00000000 0xf0200000 0x00000000 0xf0200000 0x00000000 0x01e00000 0x03000000 0x00000000 0x40000000 0x00000003 0x80000000 0x00000000 0x40000000>;
        reg-names = "dbi", "apb", "config";
        resets = <0x0000000e 0x000000c1>;
        reset-names = "pipe";
        status = "okay";
        reset-gpios = <0x00000066 0x00000018 0x00000000>;
        vpcie3v3-supply = <0x000000d4>;
        legacy-interrupt-controller {
            interrupt-controller;
            #address-cells = <0x00000000>;
            #interrupt-cells = <0x00000001>;
            interrupt-parent = <0x00000001>;
            interrupts = <0x00000000 0x000000a2 0x00000001>;
            phandle = <0x000000d3>;
        };
        ethernet@21000 {
            compatible = "realtek,rtl8125", "pci10ec,8125";
            reg = <0x00221000 0x00000000 0x00000000 0x00000000 0x00000000>;
            vid = <0x000010ec>;
            pid = <0x00008125>;
            label = "board-pci-eth1";
            status = "okay";
        };
    };
    ethernet@fe2a0000 {
        compatible = "rockchip,rk3568-gmac", "snps,dwmac-4.20a";
        reg = <0x00000000 0xfe2a0000 0x00000000 0x00010000>;
        interrupts = <0x00000000 0x0000001b 0x00000004 0x00000000 0x00000018 0x00000004>;
        interrupt-names = "macirq", "eth_wake_irq";
        clocks = <0x0000000e 0x00000182 0x0000000e 0x00000185 0x0000000e 0x00000185 0x0000000e 0x000000b8 0x0000000e 0x000000b4 0x0000000e 0x000000b5 0x0000000e 0x00000185 0x0000000e 0x000000b9 0x0000000e 0x000000ac>;
        clock-names = "stmmaceth", "mac_clk_rx", "mac_clk_tx", "clk_mac_refout", "aclk_mac", "pclk_mac", "clk_mac_speed", "ptp_ref", "pclk_xpcs";
        resets = <0x0000000e 0x000000d7>;
        reset-names = "stmmaceth";
        rockchip,grf = <0x0000001e>;
        snps,axi-config = <0x000000d5>;
        snps,mixed-burst;
        snps,mtl-rx-config = <0x000000d6>;
        snps,mtl-tx-config = <0x000000d7>;
        snps,tso;
        status = "disabled";
        mdio {
            compatible = "snps,dwmac-mdio";
            #address-cells = <0x00000001>;
            #size-cells = <0x00000000>;
        };
        stmmac-axi-config {
            snps,blen = <0x00000000 0x00000000 0x00000000 0x00000000 0x00000010 0x00000008 0x00000004>;
            snps,rd_osr_lmt = <0x00000008>;
            snps,wr_osr_lmt = <0x00000004>;
            phandle = <0x000000d5>;
        };
        rx-queues-config {
            snps,rx-queues-to-use = <0x00000001>;
            phandle = <0x000000d6>;
            queue0 {
            };
        };
        tx-queues-config {
            snps,tx-queues-to-use = <0x00000001>;
            phandle = <0x000000d7>;
            queue0 {
            };
        };
    };
    rng@fe388000 {
        compatible = "rockchip,cryptov2-rng";
        reg = <0x00000000 0xfe388000 0x00000000 0x00002000>;
        clocks = <0x0000000e 0x00000070 0x0000000e 0x0000006f>;
        clock-names = "clk_trng", "hclk_trng";
        resets = <0x0000000e 0x0000006d>;
        reset-names = "reset";
        status = "okay";
    };
    phy@fe820000 {
        compatible = "rockchip,rk3568-naneng-combphy";
        reg = <0x00000000 0xfe820000 0x00000000 0x00000100>;
        clocks = <0x0000001d 0x0000001f 0x0000000e 0x0000017c 0x0000000e 0x0000007f>;
        clock-names = "ref", "apb", "pipe";
        assigned-clocks = <0x0000001d 0x0000001f>;
        assigned-clock-rates = <0x05f5e100>;
        resets = <0x0000000e 0x000001c5>;
        reset-names = "phy";
        rockchip,pipe-grf = <0x000000bd>;
        rockchip,pipe-phy-grf = <0x000000d8>;
        #phy-cells = <0x00000001>;
        status = "okay";
        phandle = <0x00000013>;
    };
    chosen {
        stdout-path = "serial2:1500000n8";
    };
    hdmi-con {
        compatible = "hdmi-connector";
        type = "a";
        port {
            endpoint {
                remote-endpoint = <0x000000d9>;
                phandle = <0x00000063>;
            };
        };
    };
    keys {
        compatible = "gpio-keys";
        pinctrl-0 = <0x000000da>;
        pinctrl-names = "default";
        reset {
            label = "reset";
            gpios = <0x00000021 0x00000000 0x00000001>;
            linux,code = <0x00000198>;
            debounce-interval = <0x00000032>;
        };
    };
    leds {
        compatible = "gpio-leds";
        pinctrl-names = "default";
        pinctrl-0 = <0x000000db 0x000000dc 0x000000dd>;
        net {
            label = "blue:net";
            gpios = <0x0000004d 0x00000005 0x00000000>;
        };
        sata {
            label = "amber:sata";
            gpios = <0x0000004d 0x00000007 0x00000000>;
        };
        work {
            label = "green:work";
            gpios = <0x0000004d 0x00000008 0x00000000>;
        };
    };
    vcc12v-dcin {
        compatible = "regulator-fixed";
        regulator-always-on;
        regulator-boot-on;
        regulator-min-microvolt = <0x00b71b00>;
        regulator-max-microvolt = <0x00b71b00>;
        regulator-name = "vcc12v_dcin";
        phandle = <0x000000de>;
    };
    vcc3v3-sys {
        compatible = "regulator-fixed";
        regulator-always-on;
        regulator-boot-on;
        regulator-min-microvolt = <0x00325aa0>;
        regulator-max-microvolt = <0x00325aa0>;
        regulator-name = "vcc3v3_sys";
        vin-supply = <0x000000de>;
        phandle = <0x00000024>;
    };
    vcc5v0-sys {
        compatible = "regulator-fixed";
        regulator-always-on;
        regulator-boot-on;
        regulator-min-microvolt = <0x004c4b40>;
        regulator-max-microvolt = <0x004c4b40>;
        regulator-name = "vcc5v0_sys";
        vin-supply = <0x000000de>;
        phandle = <0x00000020>;
    };
    vcc5v0-usb {
        compatible = "regulator-fixed";
        regulator-always-on;
        regulator-boot-on;
        regulator-min-microvolt = <0x004c4b40>;
        regulator-max-microvolt = <0x004c4b40>;
        regulator-name = "vcc5v0_usb";
        vin-supply = <0x000000de>;
        phandle = <0x000000e0>;
    };
    vcc5v0-usb-host {
        compatible = "regulator-fixed";
        enable-active-high;
        gpio = <0x00000021 0x00000005 0x00000000>;
        pinctrl-names = "default";
        pinctrl-0 = <0x000000df>;
        regulator-min-microvolt = <0x004c4b40>;
        regulator-max-microvolt = <0x004c4b40>;
        regulator-name = "vcc5v0_usb_host";
        vin-supply = <0x000000e0>;
        phandle = <0x000000c1>;
    };
    vcc3v3-pcie {
        compatible = "regulator-fixed";
        enable-active-high;
        regulator-min-microvolt = <0x00325aa0>;
        regulator-max-microvolt = <0x00325aa0>;
        regulator-name = "vcc3v3_pcie";
        startup-delay-us = <0x00001388>;
        vin-supply = <0x00000020>;
        gpio = <0x00000021 0x00000014 0x00000000>;
        phandle = <0x00000067>;
    };
    sound {
        compatible = "simple-audio-card";
        simple-audio-card,format = "i2s";
        simple-audio-card,name = "Analog RK809";
        simple-audio-card,mclk-fs = <0x00000100>;
        simple-audio-card,cpu {
            sound-dai = <0x000000e1>;
        };
        simple-audio-card,codec {
            sound-dai = <0x000000e2>;
        };
    };
    pwm-fan {
        compatible = "pwm-fan";
        cooling-levels = <0x00000000 0x0000005a 0x00000064 0x0000006e 0x00000078 0x00000082 0x0000008c 0x00000096 0x000000a0 0x000000c8 0x000000ff>;
        #cooling-cells = <0x00000002>;
        pwms = <0x000000e3 0x00000000 0x0000c350 0x00000000>;
        phandle = <0x000000a7>;
    };
    vcc5v0-ahci {
        compatible = "regulator-fixed";
        enable-active-high;
        gpio = <0x00000021 0x00000015 0x00000000>;
        pinctrl-names = "default";
        pinctrl-0 = <0x000000e4>;
        regulator-min-microvolt = <0x004c4b40>;
        regulator-max-microvolt = <0x004c4b40>;
        regulator-name = "vcc5v0_ahci";
        vin-supply = <0x00000020>;
        phandle = <0x000000ce>;
    };
    sdio-pwrseq {
        compatible = "mmc-pwrseq-simple";
        clocks = <0x000000e2 0x00000001>;
        clock-names = "ext_clock";
        pinctrl-names = "default";
        pinctrl-0 = <0x000000e5>;
        post-power-on-delay-ms = <0x0000012c>;
        power-off-delay-us = <0x004c4b40>;
        reset-gpios = <0x0000004d 0x00000000 0x00000001>;
        phandle = <0x00000049>;
    };
    vcc3v3-pcie1 {
        compatible = "regulator-fixed";
        enable-active-high;
        regulator-min-microvolt = <0x00325aa0>;
        regulator-max-microvolt = <0x00325aa0>;
        regulator-name = "vcc3v3_pcie1";
        vin-supply = <0x00000020>;
        phandle = <0x000000d2>;
    };
    vcc3v3-pcie2 {
        compatible = "regulator-fixed";
        enable-active-high;
        regulator-min-microvolt = <0x00325aa0>;
        regulator-max-microvolt = <0x00325aa0>;
        regulator-name = "vcc3v3_pcie2";
        vin-supply = <0x00000020>;
        phandle = <0x000000d4>;
    };
};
